VERSION "..\..\trunk\components\winTestMT\code\canApi\dbcFiles\canBus_06.dbc, created by Octave and generateRandomDbc.m on 21-Feb-2017"

NS_ :

BS_:

BU_: ECU

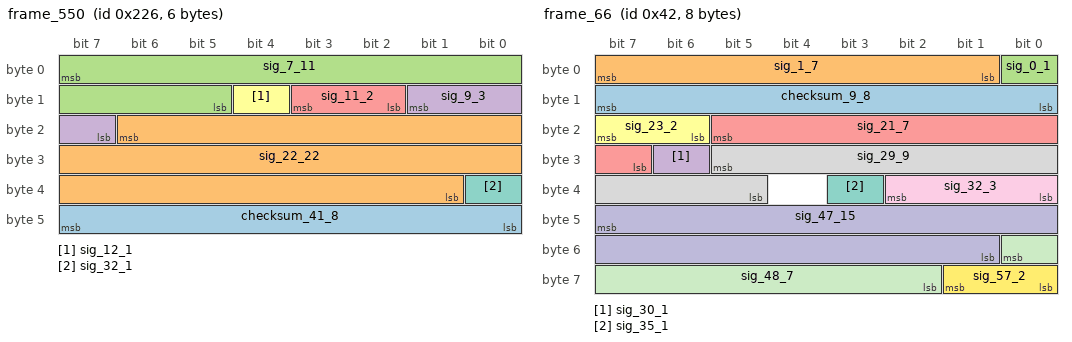
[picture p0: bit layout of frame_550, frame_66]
BO_ 550 frame_550: 6 ECU
  SG_ checksum_41_8 : 47|8@0+ (1.0,0.0) [0.0|255.0] "" Vector__XXX
  SG_ sig_22_22 : 22|22@0+ (1.0000000000000009E-9,0.0) [0.0|0.004194302000000004] "W" Vector__XXX
  SG_ sig_7_11 : 7|11@0- (0.010000000000000002,-3.1622776601683795) [-13.402277660168382|7.0577223398316224] "km/h" Vector__XXX
  SG_ sig_9_3 : 9|3@0+ (1.0,0.0) [0.0|6.0] "" Vector__XXX
  SG_ sig_11_2 : 11|2@0- (1.0,0.0) [-2.0|1.0] "" Vector__XXX
  SG_ sig_12_1 : 12|1@0+ (1.0,0.0) [0.0|1.0] "" Vector__XXX
  SG_ sig_32_1 : 32|1@0+ (1.0,0.0) [0.0|1.0] "" Vector__XXX

BO_ 794 frame_794: 7 Vector__XXX
  SG_ checksum_1_8 : 0|8@1+ (1.0,0.0) [0.0|255.0] "" ECU
  SG_ sig_10_17 : 10|17@1+ (1.0000000000000006E-5,0.0) [0.0|1.3107000000000009] "kWh" ECU
  SG_ sig_27_9 : 27|9@1+ (0.1,-31.622776601683793) [-31.622776601683793|19.377223398316207] "km/h" ECU
  SG_ sig_45_11 : 45|11@1+ (1.0000000000000008E-8,3.162277660168379E-6) [3.162277660168379E-6|2.3622277660168395E-5] "A" ECU
  SG_ sig_36_9 : 36|9@1+ (1.0,0.0) [0.0|510.0] "" ECU

BO_ 168 frame_168: 7 ECU
  SG_ checksum_41_8 : 40|8@1+ (1.0,0.0) [0.0|255.0] "" Vector__XXX
  SG_ sig_9_20 : 9|20@1- (1.0000000000000006E-5,0.0) [-5.242880000000003|5.242860000000003] "V" Vector__XXX
  SG_ sig_1_8 : 1|8@1- (1.0,0.0) [-128.0|126.0] "" Vector__XXX
  SG_ sig_29_7 : 29|7@1+ (1.0000000000000005E-4,-0.0031622776601683794) [-0.0031622776601683794|0.009437722339831625] "V" Vector__XXX
  SG_ sig_36_4 : 36|4@1+ (0.010000000000000002,-0.03162277660168379) [-0.03162277660168379|0.10837722339831622] "V" Vector__XXX
  SG_ sig_48_6 : 48|6@1- (1000.0,-31622.776601683792) [-63622.77660168379|-1622.7766016837923] "km/h" Vector__XXX
  SG_ sig_54_2 : 54|2@1+ (1.0,0.0) [0.0|3.0] "" Vector__XXX

BO_ 66 frame_66: 8 ECU
  SG_ checksum_9_8 : 8|8@1+ (1.0,0.0) [0.0|255.0] "" Vector__XXX
  SG_ sig_1_7 : 1|7@1- (0.1,0.0) [-6.4|6.2] "s" Vector__XXX
  SG_ sig_0_1 : 0|1@0+ (1.0,0.0) [0.0|1.0] "" Vector__XXX
  SG_ sig_30_1 : 30|1@1+ (1.0,0.0) [0.0|1.0] "" Vector__XXX
  SG_ sig_21_7 : 21|7@0+ (100.0,-3162.2776601683795) [-3162.2776601683795|9437.72233983162] "kWh" Vector__XXX
  SG_ sig_23_2 : 23|2@0- (1.0,0.0) [-2.0|1.0] "" Vector__XXX
  SG_ sig_35_1 : 35|1@0+ (1.0,0.0) [0.0|1.0] "" Vector__XXX
  SG_ sig_29_9 : 29|9@0- (0.010000000000000002,-3.1622776601683795) [-5.7222776601683805|-0.622277660168379] "A" Vector__XXX
  SG_ sig_32_3 : 32|3@1- (1.0,0.0) [-4.0|2.0] "" Vector__XXX
  SG_ sig_47_15 : 47|15@0+ (1.0000000000000011E-10,3.162277660168379E-6) [3.162277660168379E-6|6.438877660168383E-6] "A" Vector__XXX
  SG_ sig_48_7 : 48|7@0+ (1.0,0.0) [0.0|126.0] "" Vector__XXX
  SG_ sig_57_2 : 57|2@0+ (1.0,0.0) [0.0|3.0] "" Vector__XXX

BO_ 1387 frame_1387: 6 ECU
  SG_ checksum_17_8 : 23|8@0+ (1.0,0.0) [0.0|255.0] "" Vector__XXX
  SG_ sig_0_14 : 0|14@1- (1.0,3162.2776601683795) [-5029.72233983162|11352.27766016838] "V" Vector__XXX
  SG_ sig_14_2 : 14|2@1+ (1.0,0.0) [0.0|3.0] "" Vector__XXX
  SG_ sig_29_14 : 29|14@0- (1.0,0.0) [-8192.0|8190.0] "" Vector__XXX
  SG_ sig_31_2 : 31|2@0- (1.0,0.0) [-2.0|1.0] "" Vector__XXX
  SG_ sig_47_8 : 47|8@0+ (100.0,3162.2776601683795) [3162.2776601683795|28562.27766016838] "W" Vector__XXX

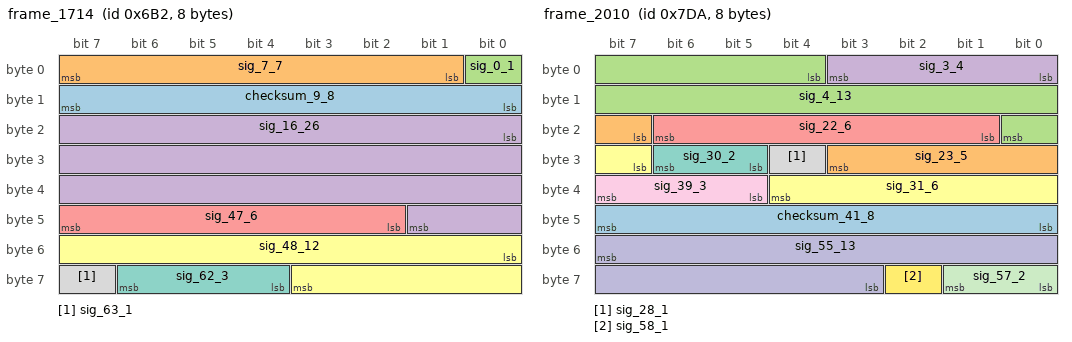
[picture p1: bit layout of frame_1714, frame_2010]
BO_ 1714 frame_1714: 8 Vector__XXX
  SG_ checksum_9_8 : 15|8@0+ (1.0,0.0) [0.0|255.0] "" ECU
  SG_ sig_7_7 : 7|7@0- (1.0,0.0) [-64.0|62.0] "" ECU
  SG_ sig_0_1 : 0|1@0+ (1.0,0.0) [0.0|1.0] "" ECU
  SG_ sig_16_26 : 16|26@1+ (1.0000000000000007E-7,3.1622776601683795) [3.1622776601683795|9.873163860168384] "W" ECU
  SG_ sig_47_6 : 47|6@0+ (1.0000000000000006E-5,0.0) [0.0|6.200000000000003E-4] "s" ECU
  SG_ sig_48_12 : 48|12@1+ (1.0,0.0) [0.0|4094.0] "" ECU
  SG_ sig_62_3 : 62|3@0- (1.0,0.0) [-4.0|2.0] "" ECU
  SG_ sig_63_1 : 63|1@1+ (1.0,0.0) [0.0|1.0] "" ECU

BO_ 2010 frame_2010: 8 Vector__XXX
  SG_ checksum_41_8 : 40|8@1+ (1.0,0.0) [0.0|255.0] "" ECU
  SG_ sig_23_5 : 23|5@1+ (1.0000000000000006E-6,3.1622776601683795E-5) [3.1622776601683795E-5|6.162277660168381E-5] "V" ECU
  SG_ sig_4_13 : 4|13@1- (1.0000000000000008E-8,3.1622776601683795E-5) [-9.33722339831624E-6|7.256277660168383E-5] "s" ECU
  SG_ sig_3_4 : 3|4@0+ (100.0,0.0) [0.0|1400.0] "kWh" ECU
  SG_ sig_22_6 : 22|6@0+ (10.0,316.22776601683796) [316.22776601683796|936.2277660168379] "kWh" ECU
  SG_ sig_31_6 : 31|6@1- (1.0,0.0) [-32.0|30.0] "" ECU
  SG_ sig_30_2 : 30|2@0- (1.0,0.0) [-2.0|1.0] "" ECU
  SG_ sig_28_1 : 28|1@1+ (1.0,0.0) [0.0|1.0] "" ECU
  SG_ sig_39_3 : 39|3@0- (1.0,0.0) [-4.0|2.0] "" ECU
  SG_ sig_55_13 : 55|13@0+ (1.0000000000000005E-4,0.31622776601683794) [0.31622776601683794|1.1352277660168384] "A" ECU
  SG_ sig_57_2 : 57|2@0+ (1.0,0.0) [0.0|3.0] "" ECU
  SG_ sig_58_1 : 58|1@0+ (1.0,0.0) [0.0|1.0] "" ECU

BO_ 300 frame_300: 7 Vector__XXX
  SG_ checksum_49_8 : 55|8@0+ (1.0,0.0) [0.0|255.0] "" ECU
  SG_ sig_12_20 : 12|20@0- (1.0,0.0) [-524288.0|524286.0] "" ECU
  SG_ sig_6_8 : 6|8@0+ (0.010000000000000002,0.0) [0.0|2.5400000000000005] "V" ECU
  SG_ sig_7_1 : 7|1@0+ (1.0,0.0) [0.0|1.0] "" ECU
  SG_ sig_14_2 : 14|2@0+ (1.0,0.0) [0.0|3.0] "" ECU
  SG_ sig_37_14 : 37|14@0+ (0.1,316.22776601683796) [316.22776601683796|1954.427766016838] "m/s^2" ECU
  SG_ sig_24_3 : 24|3@0- (1.0,0.0) [-4.0|2.0] "" ECU

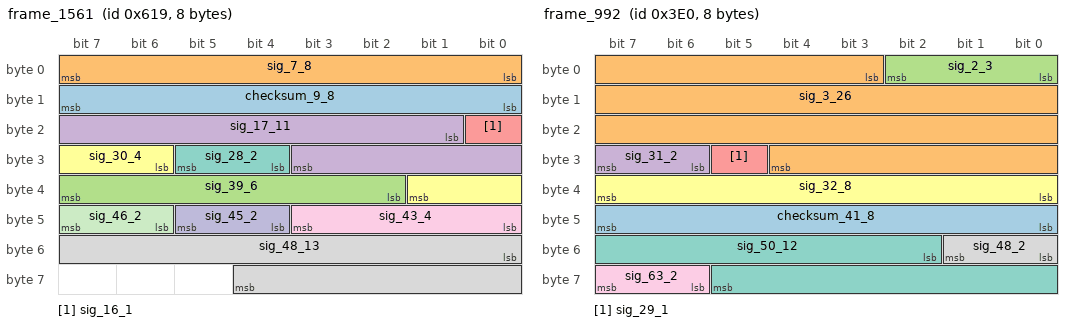
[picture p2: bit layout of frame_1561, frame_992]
BO_ 1561 frame_1561: 8 Vector__XXX
  SG_ checksum_9_8 : 8|8@1+ (1.0,0.0) [0.0|255.0] "" ECU
  SG_ sig_7_8 : 7|8@0- (10.0,0.0) [-1280.0|1260.0] "W" ECU
  SG_ sig_39_6 : 39|6@0- (1.0,0.0) [-32.0|30.0] "" ECU
  SG_ sig_17_11 : 17|11@1- (1.0,0.0) [-1024.0|1022.0] "" ECU
  SG_ sig_16_1 : 16|1@1+ (1.0,0.0) [0.0|1.0] "" ECU
  SG_ sig_30_4 : 30|4@1- (1.0,0.0) [-8.0|6.0] "" ECU
  SG_ sig_28_2 : 28|2@1- (1.0,0.0) [-2.0|1.0] "" ECU
  SG_ sig_48_13 : 48|13@1- (0.010000000000000002,31.622776601683793) [-9.337223398316215|72.5627766016838] "km/h" ECU
  SG_ sig_43_4 : 43|4@0- (1000.0,3162.2776601683795) [-4837.72233983162|9162.27766016838] "km/h" ECU
  SG_ sig_45_2 : 45|2@0+ (1.0,0.0) [0.0|3.0] "" ECU
  SG_ sig_46_2 : 46|2@1- (1.0,0.0) [-2.0|1.0] "" ECU

BO_ 992 frame_992: 8 Vector__XXX
  SG_ checksum_41_8 : 40|8@1+ (1.0,0.0) [0.0|255.0] "" ECU
  SG_ sig_3_26 : 3|26@1- (1.0000000000000005E-4,3162.2776601683795) [-193.16553983162203|6517.720660168381] "kWh" ECU
  SG_ sig_2_3 : 2|3@0+ (1.0,0.0) [0.0|6.0] "" ECU
  SG_ sig_31_2 : 31|2@0- (1.0,0.0) [-2.0|1.0] "" ECU
  SG_ sig_29_1 : 29|1@1+ (1.0,0.0) [0.0|1.0] "" ECU
  SG_ sig_32_8 : 32|8@1- (100.0,-3162.2776601683795) [-15962.27766016838|9437.72233983162] "A" ECU
  SG_ sig_50_12 : 50|12@1+ (1.0,0.0) [0.0|4094.0] "" ECU
  SG_ sig_48_2 : 48|2@1+ (1.0,0.0) [0.0|3.0] "" ECU
  SG_ sig_63_2 : 63|2@0- (1.0,0.0) [-2.0|1.0] "" ECU

BO_ 441 frame_441: 5 ECU
  SG_ checksum_9_8 : 15|8@0+ (1.0,0.0) [0.0|255.0] "" Vector__XXX
  SG_ sig_3_5 : 3|5@1+ (1000.0,-31622.776601683792) [-31622.776601683792|-1622.7766016837923] "m/s^2" Vector__XXX
  SG_ sig_0_3 : 0|3@1- (1.0,0.0) [-4.0|2.0] "" Vector__XXX
  SG_ sig_19_11 : 19|11@1+ (1.0000000000000005E-4,0.03162277660168379) [0.03162277660168379|0.2362227766016839] "kWh" Vector__XXX
  SG_ sig_16_3 : 16|3@1- (1.0,0.0) [-4.0|2.0] "" Vector__XXX
  SG_ sig_31_2 : 31|2@0- (1.0,0.0) [-2.0|1.0] "" Vector__XXX
  SG_ sig_33_7 : 33|7@1- (0.0010000000000000002,0.03162277660168379) [-0.032377223398316224|0.0936227766016838] "kWh" Vector__XXX

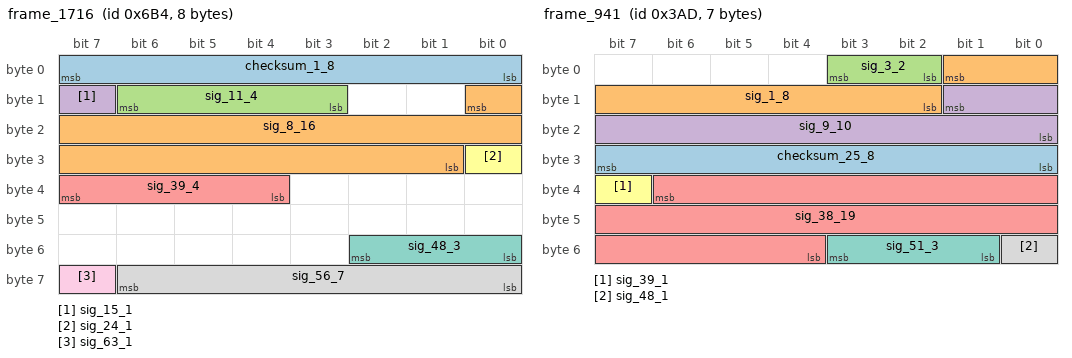
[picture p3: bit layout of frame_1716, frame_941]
BO_ 1716 frame_1716: 8 ECU
  SG_ checksum_1_8 : 0|8@1+ (1.0,0.0) [0.0|255.0] "" Vector__XXX
  SG_ sig_8_16 : 8|16@0+ (1.0,-31622.776601683792) [-31622.776601683792|33911.22339831621] "kWh" Vector__XXX
  SG_ sig_11_4 : 11|4@1- (1.0,0.0) [-8.0|6.0] "" Vector__XXX
  SG_ sig_15_1 : 15|1@0+ (1.0,0.0) [0.0|1.0] "" Vector__XXX
  SG_ sig_39_4 : 39|4@0+ (1.0,0.0) [0.0|14.0] "" Vector__XXX
  SG_ sig_24_1 : 24|1@0+ (1.0,0.0) [0.0|1.0] "" Vector__XXX
  SG_ sig_48_3 : 48|3@1- (1.0,0.0) [-4.0|2.0] "" Vector__XXX
  SG_ sig_56_7 : 56|7@1- (1.0,0.0) [-64.0|62.0] "" Vector__XXX
  SG_ sig_63_1 : 63|1@0+ (1.0,0.0) [0.0|1.0] "" Vector__XXX

BO_ 941 frame_941: 7 ECU
  SG_ checksum_25_8 : 31|8@0+ (1.0,0.0) [0.0|255.0] "" Vector__XXX
  SG_ sig_1_8 : 1|8@0+ (10.0,316.22776601683796) [316.22776601683796|2856.227766016838] "A" Vector__XXX
  SG_ sig_3_2 : 3|2@0- (1.0,0.0) [-2.0|1.0] "" Vector__XXX
  SG_ sig_9_10 : 9|10@0+ (0.0010000000000000002,-0.31622776601683794) [-0.31622776601683794|0.7057722339831622] "V" Vector__XXX
  SG_ sig_38_19 : 38|19@0- (0.1,-31622.776601683792) [-57837.176601683794|-5408.5766016837915] "s" Vector__XXX
  SG_ sig_39_1 : 39|1@0+ (1.0,0.0) [0.0|1.0] "" Vector__XXX
  SG_ sig_51_3 : 51|3@0+ (1.0,0.0) [0.0|6.0] "" Vector__XXX
  SG_ sig_48_1 : 48|1@0+ (1.0,0.0) [0.0|1.0] "" Vector__XXX

BO_ 157 frame_157: 6 Vector__XXX
  SG_ checksum_41_8 : 47|8@0+ (1.0,0.0) [0.0|255.0] "" ECU
  SG_ sig_14_26 : 14|26@0- (1.0000000000000007E-7,-3.1622776601683795) [-6.517720860168382|0.19316533983162287] "V" ECU
  SG_ sig_7_9 : 7|9@0+ (100.0,31622.776601683792) [31622.776601683792|82622.77660168378] "kWh" ECU
  SG_ sig_32_5 : 32|5@1+ (0.010000000000000002,-0.31622776601683794) [-0.31622776601683794|-0.016227766016837897] "kWh" ECU

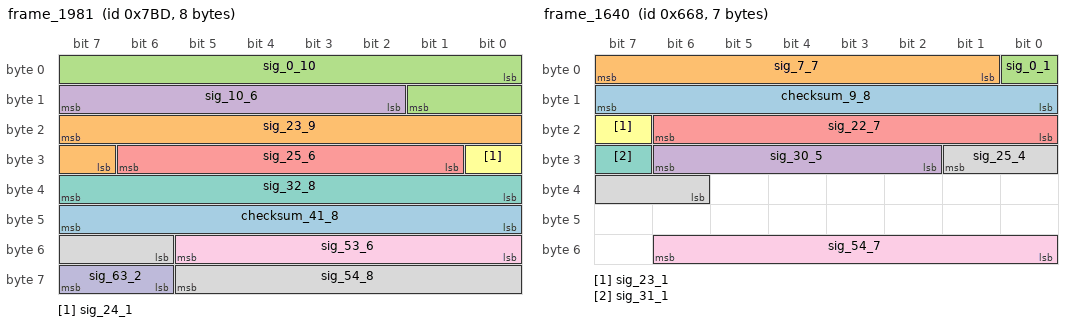
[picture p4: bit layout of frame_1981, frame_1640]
BO_ 1981 frame_1981: 8 Vector__XXX
  SG_ checksum_41_8 : 47|8@0+ (1.0,0.0) [0.0|255.0] "" ECU
  SG_ sig_23_9 : 23|9@0+ (1.0,316.22776601683796) [316.22776601683796|826.2277660168379] "W" ECU
  SG_ sig_0_10 : 0|10@1+ (1.0,0.0) [0.0|1022.0] "" ECU
  SG_ sig_10_6 : 10|6@1+ (1.0,0.0) [0.0|62.0] "m/s^2" ECU
  SG_ sig_25_6 : 25|6@1+ (1.0,0.0) [0.0|62.0] "" ECU
  SG_ sig_24_1 : 24|1@1+ (1.0,0.0) [0.0|1.0] "" ECU
  SG_ sig_32_8 : 32|8@1- (1.0,0.0) [-128.0|126.0] "" ECU
  SG_ sig_54_8 : 54|8@1+ (1.0,-31.622776601683793) [-31.622776601683793|222.3772233983162] "km/h" ECU
  SG_ sig_53_6 : 53|6@0- (1.0000000000000005E-4,-0.0031622776601683794) [-0.006362277660168381|-1.6227766016837803E-4] "W" ECU
  SG_ sig_63_2 : 63|2@0+ (1.0,0.0) [0.0|3.0] "" ECU

BO_ 1640 frame_1640: 7 ECU
  SG_ checksum_9_8 : 15|8@0+ (1.0,0.0) [0.0|255.0] "" Vector__XXX
  SG_ sig_7_7 : 7|7@0- (10.0,0.0) [-640.0|620.0] "V" Vector__XXX
  SG_ sig_0_1 : 0|1@0+ (1.0,0.0) [0.0|1.0] "" Vector__XXX
  SG_ sig_30_5 : 30|5@0+ (1.0,0.0) [0.0|30.0] "" Vector__XXX
  SG_ sig_22_7 : 22|7@0+ (0.1,0.0) [0.0|12.600000000000001] "V" Vector__XXX
  SG_ sig_23_1 : 23|1@0+ (1.0,0.0) [0.0|1.0] "" Vector__XXX
  SG_ sig_31_1 : 31|1@0+ (1.0,0.0) [0.0|1.0] "" Vector__XXX
  SG_ sig_25_4 : 25|4@0- (1.0,0.0) [-8.0|6.0] "" Vector__XXX
  SG_ sig_54_7 : 54|7@0+ (1.0,0.0) [0.0|126.0] "" Vector__XXX

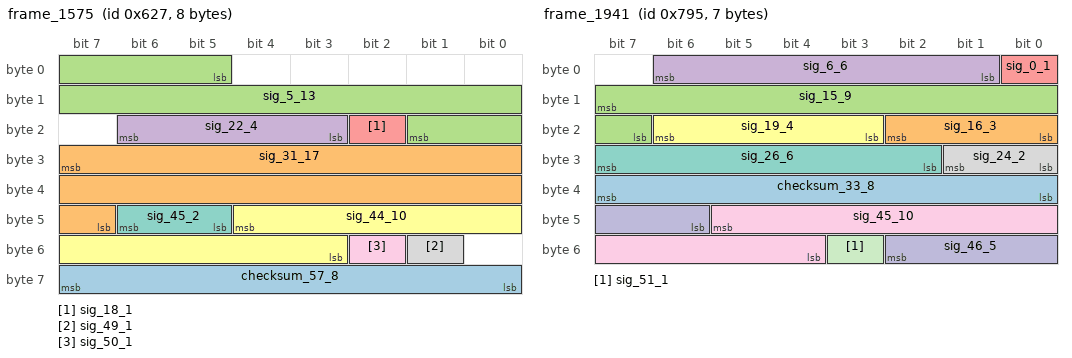
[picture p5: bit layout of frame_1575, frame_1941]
BO_ 1575 frame_1575: 8 ECU
  SG_ checksum_57_8 : 56|8@1+ (1.0,0.0) [0.0|255.0] "" Vector__XXX
  SG_ sig_31_17 : 31|17@0- (1.0,31622.776601683792) [-33913.22339831621|97156.77660168378] "W" Vector__XXX
  SG_ sig_5_13 : 5|13@1- (1.0,0.0) [-4096.0|4094.0] "" Vector__XXX
  SG_ sig_22_4 : 22|4@0+ (10000.0,-31622.776601683792) [-31622.776601683792|108377.22339831622] "kWh" Vector__XXX
  SG_ sig_18_1 : 18|1@0+ (1.0,0.0) [0.0|1.0] "" Vector__XXX
  SG_ sig_44_10 : 44|10@0- (1.0,316.22776601683796) [-195.77223398316204|826.2277660168379] "W" Vector__XXX
  SG_ sig_45_2 : 45|2@1- (1.0,0.0) [-2.0|1.0] "" Vector__XXX
  SG_ sig_49_1 : 49|1@1+ (1.0,0.0) [0.0|1.0] "" Vector__XXX
  SG_ sig_50_1 : 50|1@0+ (1.0,0.0) [0.0|1.0] "" Vector__XXX

BO_ 1169 frame_1169: 8 Vector__XXX
  SG_ checksum_49_8 : 48|8@1+ (1.0,0.0) [0.0|255.0] "" ECU
  SG_ sig_4_20 : 4|20@0- (0.1,-31622.776601683792) [-84051.5766016838|20805.823398316214] "s" ECU
  SG_ sig_5_2 : 5|2@1- (1.0,0.0) [-2.0|1.0] "" ECU
  SG_ sig_29_19 : 29|19@0- (1.0000000000000006E-6,0.31622776601683794) [0.054083766016837787|0.5783697660168381] "kWh" ECU
  SG_ sig_16_1 : 16|1@1+ (1.0,0.0) [0.0|1.0] "" ECU
  SG_ sig_31_2 : 31|2@0- (1.0,0.0) [-2.0|1.0] "" ECU
  SG_ sig_56_7 : 56|7@1+ (1.0000000000000005E-4,-0.0031622776601683794) [-0.0031622776601683794|0.009437722339831625] "kWh" ECU

BO_ 1941 frame_1941: 7 Vector__XXX
  SG_ checksum_33_8 : 39|8@0+ (1.0,0.0) [0.0|255.0] "" ECU
  SG_ sig_16_3 : 16|3@1+ (1.0,0.0) [0.0|6.0] "" ECU
  SG_ sig_15_9 : 15|9@0- (1.0,0.0) [-256.0|254.0] "" ECU
  SG_ sig_6_6 : 6|6@0+ (100.0,0.0) [0.0|6200.0] "V" ECU
  SG_ sig_0_1 : 0|1@1+ (1.0,0.0) [0.0|1.0] "" ECU
  SG_ sig_19_4 : 19|4@1- (1.0,-3.1622776601683795) [-11.16227766016838|2.8377223398316205] "V" ECU
  SG_ sig_26_6 : 26|6@1+ (10.0,-316.22776601683796) [-316.22776601683796|303.77223398316204] "m/s^2" ECU
  SG_ sig_24_2 : 24|2@1- (1.0,0.0) [-2.0|1.0] "" ECU
  SG_ sig_45_10 : 45|10@0- (1.0000000000000007E-7,0.0) [-5.120000000000004E-5|5.100000000000004E-5] "s" ECU
  SG_ sig_46_5 : 46|5@1+ (10.0,0.0) [0.0|300.0] "W" ECU
  SG_ sig_51_1 : 51|1@0+ (1.0,0.0) [0.0|1.0] "" ECU

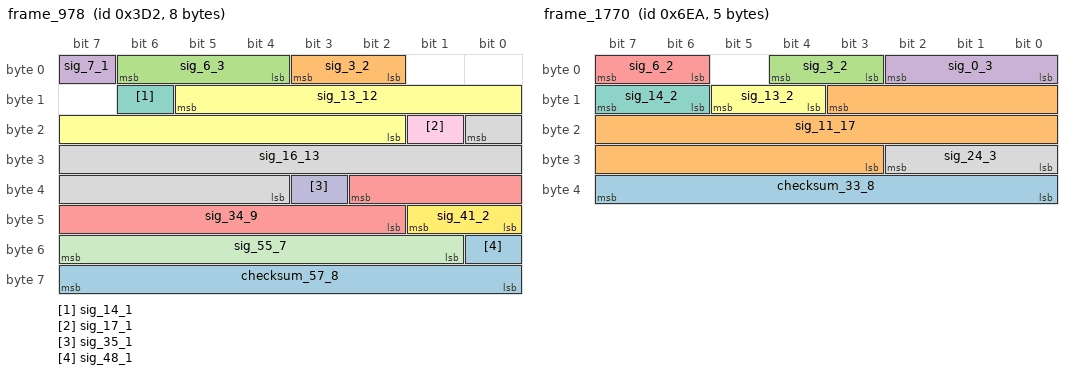
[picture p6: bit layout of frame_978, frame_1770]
BO_ 978 frame_978: 8 Vector__XXX
  SG_ checksum_57_8 : 63|8@0+ (1.0,0.0) [0.0|255.0] "" ECU
  SG_ sig_3_2 : 3|2@0+ (1.0,0.0) [0.0|3.0] "" ECU
  SG_ sig_6_3 : 6|3@0- (1.0,0.0) [-4.0|2.0] "" ECU
  SG_ sig_7_1 : 7|1@0+ (1.0,0.0) [0.0|1.0] "" ECU
  SG_ sig_34_9 : 34|9@0+ (1.0000000000000008E-8,0.0) [0.0|5.1000000000000045E-6] "s" ECU
  SG_ sig_13_12 : 13|12@0+ (1.0,0.0) [0.0|4094.0] "" ECU
  SG_ sig_14_1 : 14|1@0+ (1.0,0.0) [0.0|1.0] "" ECU
  SG_ sig_16_13 : 16|13@0- (1.0000000000000005E-4,0.31622776601683794) [-0.09337223398316224|0.7256277660168382] "m/s^2" ECU
  SG_ sig_17_1 : 17|1@0+ (1.0,0.0) [0.0|1.0] "" ECU
  SG_ sig_35_1 : 35|1@0+ (1.0,0.0) [0.0|1.0] "" ECU
  SG_ sig_55_7 : 55|7@0- (1.0,0.0) [-64.0|62.0] "" ECU
  SG_ sig_41_2 : 41|2@0+ (1.0,0.0) [0.0|3.0] "" ECU
  SG_ sig_48_1 : 48|1@0+ (1.0,0.0) [0.0|1.0] "" ECU

BO_ 1155 frame_1155: 5 Vector__XXX
  SG_ checksum_1_8 : 7|8@0+ (1.0,0.0) [0.0|255.0] "" ECU
  SG_ sig_19_19 : 19|19@1- (0.0010000000000000002,316.22776601683796) [54.0837660168379|578.369766016838] "m/s^2" ECU
  SG_ sig_15_5 : 15|5@0- (1.0000000000000006E-5,-3.1622776601683794E-4) [-4.7622776601683803E-4|-1.7622776601683784E-4] "W" ECU
  SG_ sig_8_3 : 8|3@1+ (1.0,0.0) [0.0|6.0] "" ECU
  SG_ sig_16_3 : 16|3@1- (1.0,0.0) [-4.0|2.0] "" ECU
  SG_ sig_39_1 : 39|1@0+ (1.0,0.0) [0.0|1.0] "" ECU
  SG_ sig_38_1 : 38|1@0+ (1.0,0.0) [0.0|1.0] "" ECU

BO_ 1971 frame_1971: 4 Vector__XXX
  SG_ checksum_17_8 : 16|8@1+ (1.0,0.0) [0.0|255.0] "" ECU
  SG_ sig_0_15 : 0|15@1+ (0.1,-3162.2776601683795) [-3162.2776601683795|114.32233983162087] "s" ECU
  SG_ sig_15_1 : 15|1@1+ (1.0,0.0) [0.0|1.0] "" ECU
  SG_ sig_25_7 : 25|7@1+ (1.0000000000000007E-7,0.0) [0.0|1.260000000000001E-5] "A" ECU
  SG_ sig_24_1 : 24|1@1+ (1.0,0.0) [0.0|1.0] "" ECU

BO_ 1838 frame_1838: 7 Vector__XXX
  SG_ checksum_41_8 : 47|8@0+ (1.0,0.0) [0.0|255.0] "" ECU
  SG_ sig_12_20 : 12|20@0+ (1.000000000000001E-11,3.162277660168379E-6) [3.162277660168379E-6|1.364801766016839E-5] "m/s^2" ECU
  SG_ sig_7_7 : 7|7@0+ (1.0000000000000005E-4,-0.0031622776601683794) [-0.0031622776601683794|0.009437722339831625] "V" ECU
  SG_ sig_32_5 : 32|5@1+ (1.0,0.0) [0.0|30.0] "" ECU
  SG_ sig_38_2 : 38|2@0- (1.0,0.0) [-2.0|1.0] "" ECU
  SG_ sig_49_7 : 49|7@1- (1.0,0.0) [-64.0|62.0] "" ECU
  SG_ sig_48_1 : 48|1@0+ (1.0,0.0) [0.0|1.0] "" ECU

BO_ 1770 frame_1770: 5 Vector__XXX
  SG_ checksum_33_8 : 39|8@0+ (1.0,0.0) [0.0|255.0] "" ECU
  SG_ sig_11_17 : 11|17@0+ (0.1,-3162.2776601683795) [-3162.2776601683795|9944.72233983162] "kWh" ECU
  SG_ sig_3_2 : 3|2@1- (1.0,0.0) [-2.0|1.0] "" ECU
  SG_ sig_0_3 : 0|3@1+ (1.0,0.0) [0.0|6.0] "" ECU
  SG_ sig_6_2 : 6|2@1- (1.0,0.0) [-2.0|1.0] "" ECU
  SG_ sig_13_2 : 13|2@0+ (1.0,0.0) [0.0|3.0] "" ECU
  SG_ sig_14_2 : 14|2@1+ (1.0,0.0) [0.0|3.0] "" ECU
  SG_ sig_24_3 : 24|3@1- (1.0,0.0) [-4.0|2.0] "" ECU

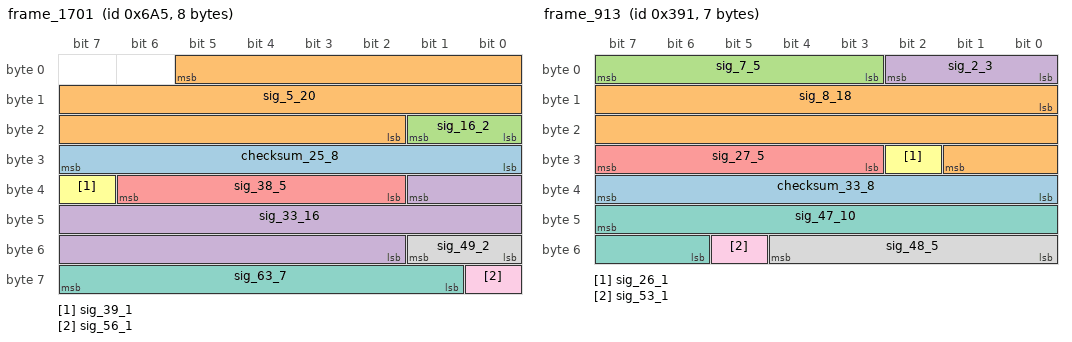
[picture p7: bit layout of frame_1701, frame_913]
BO_ 1701 frame_1701: 8 Vector__XXX
  SG_ checksum_25_8 : 31|8@0+ (1.0,0.0) [0.0|255.0] "" ECU
  SG_ sig_5_20 : 5|20@0+ (1.0,0.0) [0.0|1048574.0] "" ECU
  SG_ sig_16_2 : 16|2@1+ (1.0,0.0) [0.0|3.0] "" ECU
  SG_ sig_33_16 : 33|16@0- (1.0000000000000008E-8,3.1622776601683794E-4) [-1.1452233983162338E-5|6.438877660168382E-4] "W" ECU
  SG_ sig_38_5 : 38|5@0- (1.0,0.0) [-16.0|14.0] "" ECU
  SG_ sig_39_1 : 39|1@1+ (1.0,0.0) [0.0|1.0] "" ECU
  SG_ sig_63_7 : 63|7@0+ (1000.0,0.0) [0.0|126000.0] "A" ECU
  SG_ sig_49_2 : 49|2@0- (1.0,0.0) [-2.0|1.0] "" ECU
  SG_ sig_56_1 : 56|1@0+ (1.0,0.0) [0.0|1.0] "" ECU

BO_ 1727 frame_1727: 4 Vector__XXX
  SG_ checksum_9_8 : 8|8@1+ (1.0,0.0) [0.0|255.0] "" ECU
  SG_ sig_7_7 : 7|7@0+ (1.0,0.0) [0.0|126.0] "" ECU
  SG_ sig_0_1 : 0|1@1+ (1.0,0.0) [0.0|1.0] "" ECU
  SG_ sig_22_6 : 22|6@1+ (100.0,0.0) [0.0|6200.0] "A" ECU
  SG_ sig_17_5 : 17|5@1+ (1.0000000000000005E-4,0.0031622776601683794) [0.0031622776601683794|0.006162277660168381] "A" ECU
  SG_ sig_31_4 : 31|4@0- (10000.0,-31622.776601683792) [-111622.77660168378|28377.223398316208] "V" ECU
  SG_ sig_16_1 : 16|1@1+ (1.0,0.0) [0.0|1.0] "" ECU

BO_ 1329 frame_1329: 4 Vector__XXX
  SG_ checksum_17_8 : 23|8@0+ (1.0,0.0) [0.0|255.0] "" ECU
  SG_ sig_2_11 : 2|11@0- (0.010000000000000002,0.0) [-10.240000000000002|10.220000000000002] "s" ECU
  SG_ sig_3_5 : 3|5@1+ (10.0,0.0) [0.0|300.0] "W" ECU
  SG_ sig_24_7 : 24|7@1+ (1.0000000000000007E-7,-3.162277660168379E-6) [-3.162277660168379E-6|9.43772233983163E-6] "m/s^2" ECU
  SG_ sig_31_1 : 31|1@1+ (1.0,0.0) [0.0|1.0] "" ECU

BO_ 1272 frame_1272: 6 ECU
  SG_ checksum_25_8 : 31|8@0+ (1.0,0.0) [0.0|255.0] "" Vector__XXX
  SG_ sig_4_12 : 4|12@1- (1.0000000000000009E-9,0.0) [-2.048000000000002E-6|2.0460000000000017E-6] "km/h" Vector__XXX
  SG_ sig_2_3 : 2|3@0- (1.0,0.0) [-4.0|2.0] "" Vector__XXX
  SG_ sig_3_1 : 3|1@0+ (1.0,0.0) [0.0|1.0] "" Vector__XXX
  SG_ sig_23_8 : 23|8@0- (1.0000000000000006E-5,-3.1622776601683794E-4) [-0.0015962277660168387|9.437722339831628E-4] "W" Vector__XXX
  SG_ sig_36_12 : 36|12@0+ (1.0000000000000006E-5,0.0) [0.0|0.040940000000000025] "A" Vector__XXX
  SG_ sig_37_4 : 37|4@1- (1.0,0.0) [-8.0|6.0] "" Vector__XXX

BO_ 913 frame_913: 7 ECU
  SG_ checksum_33_8 : 39|8@0+ (1.0,0.0) [0.0|255.0] "" Vector__XXX
  SG_ sig_8_18 : 8|18@1+ (1.0,0.0) [0.0|262142.0] "" Vector__XXX
  SG_ sig_7_5 : 7|5@0- (1.0000000000000007E-7,0.0) [-1.6000000000000012E-6|1.400000000000001E-6] "s" Vector__XXX
  SG_ sig_2_3 : 2|3@0- (1.0,0.0) [-4.0|2.0] "" Vector__XXX
  SG_ sig_27_5 : 27|5@1+ (1.0,31.622776601683793) [31.622776601683793|61.622776601683796] "m/s^2" Vector__XXX
  SG_ sig_26_1 : 26|1@1+ (1.0,0.0) [0.0|1.0] "" Vector__XXX
  SG_ sig_47_10 : 47|10@0+ (1.0,0.0) [0.0|1022.0] "" Vector__XXX
  SG_ sig_48_5 : 48|5@1+ (1.0000000000000006E-5,-3.1622776601683794E-4) [-3.1622776601683794E-4|-1.622776601683775E-5] "kWh" Vector__XXX
  SG_ sig_53_1 : 53|1@0+ (1.0,0.0) [0.0|1.0] "" Vector__XXX

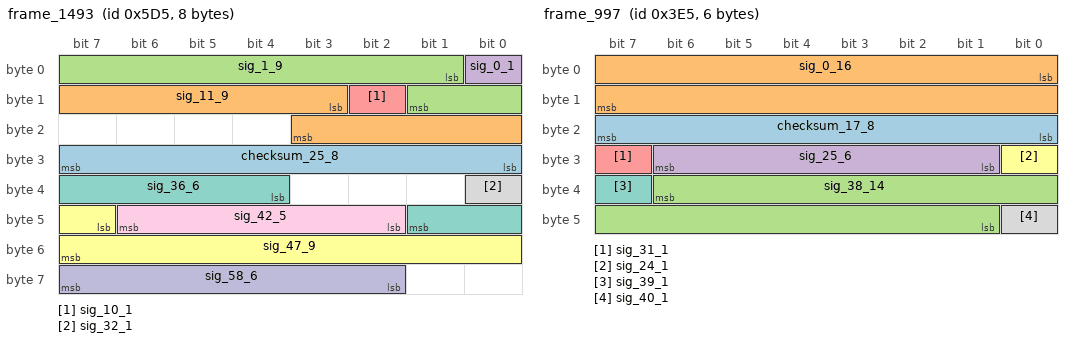
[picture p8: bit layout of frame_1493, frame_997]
BO_ 1493 frame_1493: 8 Vector__XXX
  SG_ checksum_25_8 : 24|8@1+ (1.0,0.0) [0.0|255.0] "" ECU
  SG_ sig_11_9 : 11|9@1- (1.0,0.0) [-256.0|254.0] "" ECU
  SG_ sig_1_9 : 1|9@1+ (1.0000000000000007E-7,3.1622776601683795E-5) [3.1622776601683795E-5|8.262277660168384E-5] "W" ECU
  SG_ sig_0_1 : 0|1@1+ (1.0,0.0) [0.0|1.0] "" ECU
  SG_ sig_10_1 : 10|1@1+ (1.0,0.0) [0.0|1.0] "" ECU
  SG_ sig_47_9 : 47|9@1- (1.0,0.0) [-256.0|254.0] "" ECU
  SG_ sig_36_6 : 36|6@1- (1.0000000000000006E-5,0.0) [-3.200000000000002E-4|3.000000000000002E-4] "m/s^2" ECU
  SG_ sig_32_1 : 32|1@1+ (1.0,0.0) [0.0|1.0] "" ECU
  SG_ sig_42_5 : 42|5@1- (1.0,0.0) [-16.0|14.0] "" ECU
  SG_ sig_58_6 : 58|6@1- (10.0,0.0) [-320.0|300.0] "kWh" ECU

BO_ 1165 frame_1165: 4 ECU
  SG_ checksum_17_8 : 23|8@0+ (1.0,0.0) [0.0|255.0] "" Vector__XXX
  SG_ sig_6_14 : 6|14@0- (0.1,-316.22776601683796) [-1135.427766016838|502.77223398316204] "km/h" Vector__XXX
  SG_ sig_7_1 : 7|1@0+ (1.0,0.0) [0.0|1.0] "" Vector__XXX
  SG_ sig_8_1 : 8|1@0+ (1.0,0.0) [0.0|1.0] "" Vector__XXX
  SG_ sig_31_2 : 31|2@0+ (1.0,0.0) [0.0|3.0] "" Vector__XXX
  SG_ sig_24_1 : 24|1@0+ (1.0,0.0) [0.0|1.0] "" Vector__XXX

BO_ 997 frame_997: 6 Vector__XXX
  SG_ checksum_17_8 : 16|8@1+ (1.0,0.0) [0.0|255.0] "" ECU
  SG_ sig_0_16 : 0|16@1- (0.1,3162.2776601683795) [-114.52233983162068|6438.87766016838] "m/s^2" ECU
  SG_ sig_38_14 : 38|14@0+ (1.0000000000000006E-5,0.03162277660168379) [0.03162277660168379|0.1954427766016839] "s" ECU
  SG_ sig_25_6 : 25|6@1- (1.0000000000000005E-4,-0.0031622776601683794) [-0.006362277660168381|-1.6227766016837803E-4] "s" ECU
  SG_ sig_31_1 : 31|1@0+ (1.0,0.0) [0.0|1.0] "" ECU
  SG_ sig_24_1 : 24|1@1+ (1.0,0.0) [0.0|1.0] "" ECU
  SG_ sig_39_1 : 39|1@0+ (1.0,0.0) [0.0|1.0] "" ECU
  SG_ sig_40_1 : 40|1@1+ (1.0,0.0) [0.0|1.0] "" ECU

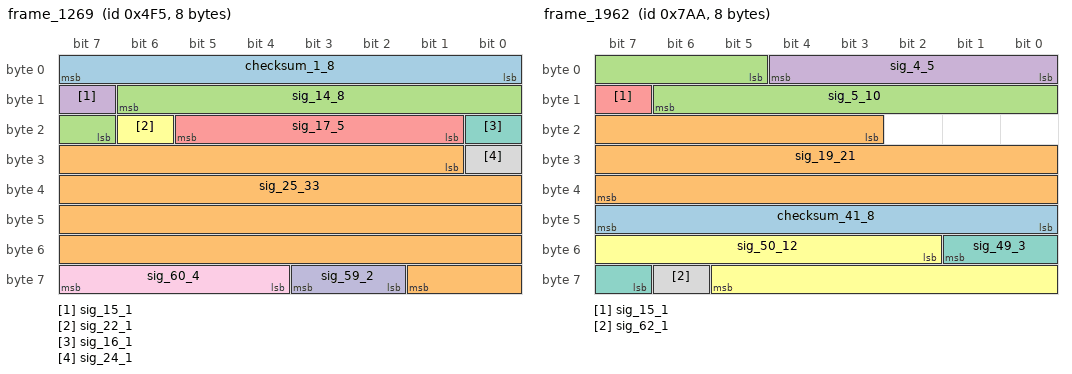
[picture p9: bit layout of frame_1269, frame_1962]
BO_ 1269 frame_1269: 8 Vector__XXX
  SG_ checksum_1_8 : 7|8@0+ (1.0,0.0) [0.0|255.0] "" ECU
  SG_ sig_25_33 : 25|33@1+ (1.0000000000000006E-6,-3162.2776601683795) [-3162.2776601683795|5427.656929831624] "m/s^2" ECU
  SG_ sig_14_8 : 14|8@0+ (1.0000000000000007E-7,-3.162277660168379E-6) [-3.162277660168379E-6|2.2237722339831637E-5] "kWh" ECU
  SG_ sig_15_1 : 15|1@0+ (1.0,0.0) [0.0|1.0] "" ECU
  SG_ sig_17_5 : 17|5@1+ (1.0,0.0) [0.0|30.0] "" ECU
  SG_ sig_22_1 : 22|1@0+ (1.0,0.0) [0.0|1.0] "" ECU
  SG_ sig_16_1 : 16|1@0+ (1.0,0.0) [0.0|1.0] "" ECU
  SG_ sig_24_1 : 24|1@0+ (1.0,0.0) [0.0|1.0] "" ECU
  SG_ sig_60_4 : 60|4@1- (100.0,316.22776601683796) [-483.77223398316204|916.2277660168379] "s" ECU
  SG_ sig_59_2 : 59|2@0+ (1.0,0.0) [0.0|3.0] "" ECU

BO_ 1962 frame_1962: 8 Vector__XXX
  SG_ checksum_41_8 : 47|8@0+ (1.0,0.0) [0.0|255.0] "" ECU
  SG_ sig_19_21 : 19|21@1+ (1.000000000000001E-11,3.162277660168379E-6) [3.162277660168379E-6|2.41337776601684E-5] "km/h" ECU
  SG_ sig_5_10 : 5|10@1+ (10.0,3162.2776601683795) [3162.2776601683795|13382.27766016838] "m/s^2" ECU
  SG_ sig_4_5 : 4|5@0+ (1.0,0.0) [0.0|30.0] "" ECU
  SG_ sig_15_1 : 15|1@0+ (1.0,0.0) [0.0|1.0] "" ECU
  SG_ sig_50_12 : 50|12@1- (1.0000000000000005E-4,-0.31622776601683794) [-0.5210277660168381|-0.11162776601683785] "A" ECU
  SG_ sig_49_3 : 49|3@0+ (1.0,0.0) [0.0|6.0] "" ECU
  SG_ sig_62_1 : 62|1@1+ (1.0,0.0) [0.0|1.0] "" ECU

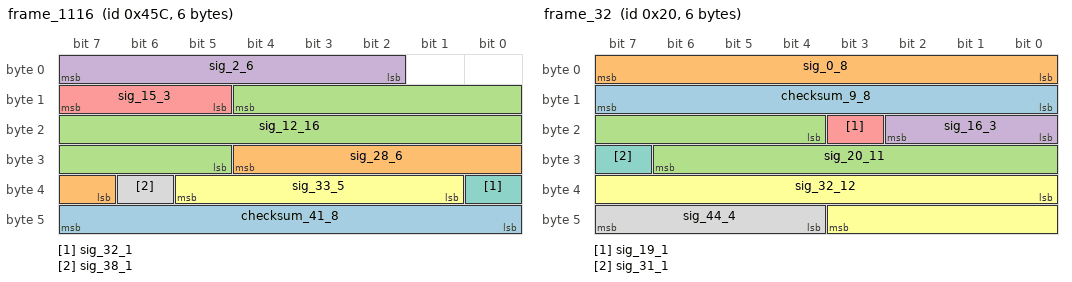
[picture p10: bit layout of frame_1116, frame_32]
BO_ 1116 frame_1116: 6 Vector__XXX
  SG_ checksum_41_8 : 40|8@1+ (1.0,0.0) [0.0|255.0] "" ECU
  SG_ sig_28_6 : 28|6@0- (1.0,-31.622776601683793) [-63.622776601683796|-1.6227766016837926] "kWh" ECU
  SG_ sig_12_16 : 12|16@0- (1.0000000000000006E-5,0.0) [-0.3276800000000002|0.3276600000000002] "W" ECU
  SG_ sig_2_6 : 2|6@1- (0.010000000000000002,-0.31622776601683794) [-0.6362277660168381|-0.016227766016837897] "A" ECU
  SG_ sig_15_3 : 15|3@0+ (1.0,0.0) [0.0|6.0] "" ECU
  SG_ sig_33_5 : 33|5@1- (1.0,0.0) [-16.0|14.0] "" ECU
  SG_ sig_32_1 : 32|1@1+ (1.0,0.0) [0.0|1.0] "" ECU
  SG_ sig_38_1 : 38|1@0+ (1.0,0.0) [0.0|1.0] "" ECU

BO_ 32 frame_32: 6 Vector__XXX
  SG_ checksum_9_8 : 8|8@1+ (1.0,0.0) [0.0|255.0] "" ECU
  SG_ sig_0_8 : 0|8@1+ (1.0,0.0) [0.0|254.0] "" ECU
  SG_ sig_20_11 : 20|11@1- (10.0,0.0) [-10240.0|10220.0] "m/s^2" ECU
  SG_ sig_16_3 : 16|3@1- (1.0,0.0) [-4.0|2.0] "" ECU
  SG_ sig_19_1 : 19|1@1+ (1.0,0.0) [0.0|1.0] "" ECU
  SG_ sig_32_12 : 32|12@1- (1.0,0.0) [-2048.0|2046.0] "" ECU
  SG_ sig_31_1 : 31|1@1+ (1.0,0.0) [0.0|1.0] "" ECU
  SG_ sig_44_4 : 44|4@1+ (1000.0,0.0) [0.0|14000.0] "V" ECU

BO_ 895 frame_895: 3 ECU
  SG_ checksum_9_8 : 8|8@1+ (1.0,0.0) [0.0|255.0] "" Vector__XXX
  SG_ sig_0_5 : 0|5@1+ (0.0010000000000000002,0.0) [0.0|0.030000000000000006] "kWh" Vector__XXX
  SG_ sig_7_3 : 7|3@0+ (1.0,0.0) [0.0|6.0] "" Vector__XXX
  SG_ sig_22_7 : 22|7@0+ (1.0,0.0) [0.0|126.0] "" Vector__XXX
  SG_ sig_23_1 : 23|1@1+ (1.0,0.0) [0.0|1.0] "" Vector__XXX

BO_ 1479 frame_1479: 5 Vector__XXX
  SG_ checksum_1_8 : 7|8@0+ (1.0,0.0) [0.0|255.0] "" ECU
  SG_ sig_23_9 : 23|9@0+ (1.0,0.0) [0.0|510.0] "" ECU
  SG_ sig_8_8 : 8|8@1+ (1.0,0.0) [0.0|254.0] "" ECU
  SG_ sig_27_12 : 27|12@0- (1.0,0.0) [-2048.0|2046.0] "" ECU
  SG_ sig_30_2 : 30|2@0+ (1.0,0.0) [0.0|3.0] "" ECU
  SG_ sig_28_1 : 28|1@0+ (1.0,0.0) [0.0|1.0] "" ECU

BO_ 666 frame_666: 3 ECU
  SG_ checksum_9_8 : 15|8@0+ (1.0,0.0) [0.0|255.0] "" Vector__XXX
  SG_ sig_4_5 : 4|5@0- (100.0,0.0) [-1600.0|1400.0] "V" Vector__XXX
  SG_ sig_5_2 : 5|2@1- (1.0,0.0) [-2.0|1.0] "" Vector__XXX
  SG_ sig_23_7 : 23|7@0- (0.0010000000000000002,0.0) [-0.06400000000000002|0.06200000000000001] "A" Vector__XXX
  SG_ sig_16_1 : 16|1@0+ (1.0,0.0) [0.0|1.0] "" Vector__XXX

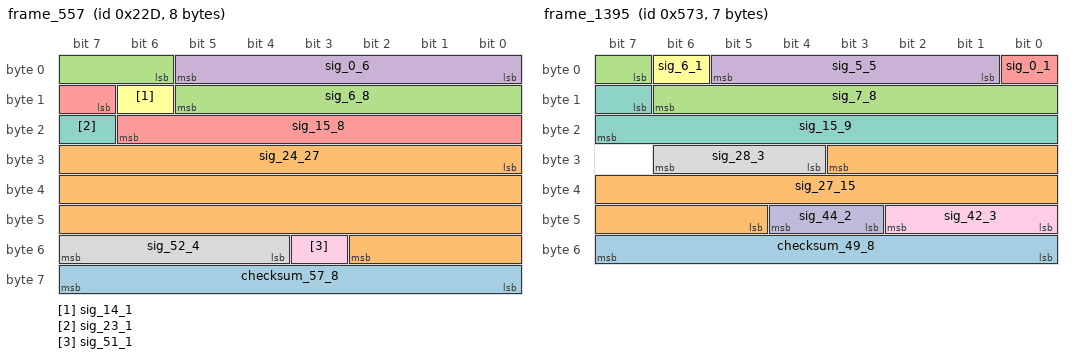
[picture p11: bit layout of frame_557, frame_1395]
BO_ 557 frame_557: 8 Vector__XXX
  SG_ checksum_57_8 : 56|8@1+ (1.0,0.0) [0.0|255.0] "" ECU
  SG_ sig_24_27 : 24|27@1+ (1.0000000000000009E-9,-0.03162277660168379) [-0.03162277660168379|0.10259494939831633] "s" ECU
  SG_ sig_6_8 : 6|8@1+ (1.0,0.0) [0.0|254.0] "" ECU
  SG_ sig_0_6 : 0|6@1- (100.0,3162.2776601683795) [-37.7223398316205|6162.27766016838] "A" ECU
  SG_ sig_15_8 : 15|8@1- (10.0,0.0) [-1280.0|1260.0] "s" ECU
  SG_ sig_14_1 : 14|1@1+ (1.0,0.0) [0.0|1.0] "" ECU
  SG_ sig_23_1 : 23|1@1+ (1.0,0.0) [0.0|1.0] "" ECU
  SG_ sig_52_4 : 52|4@1+ (0.0010000000000000002,-0.0031622776601683794) [-0.0031622776601683794|0.010837722339831624] "kWh" ECU
  SG_ sig_51_1 : 51|1@1+ (1.0,0.0) [0.0|1.0] "" ECU

BO_ 1857 frame_1857: 5 Vector__XXX
  SG_ checksum_1_8 : 7|8@0+ (1.0,0.0) [0.0|255.0] "" ECU
  SG_ sig_21_16 : 21|16@0- (1.0000000000000006E-5,-0.31622776601683794) [-0.6439077660168382|0.011432233983162232] "A" ECU
  SG_ sig_15_10 : 15|10@0+ (0.1,31.622776601683793) [31.622776601683793|133.82277660168378] "kWh" ECU
  SG_ sig_37_5 : 37|5@0- (1000.0,0.0) [-16000.0|14000.0] "km/h" ECU
  SG_ sig_32_1 : 32|1@0+ (1.0,0.0) [0.0|1.0] "" ECU

BO_ 1395 frame_1395: 7 Vector__XXX
  SG_ checksum_49_8 : 48|8@1+ (1.0,0.0) [0.0|255.0] "" ECU
  SG_ sig_27_15 : 27|15@0+ (1.0000000000000007E-7,-0.0031622776601683794) [-0.0031622776601683794|1.1432233983162295E-4] "A" ECU
  SG_ sig_7_8 : 7|8@1+ (1.0,0.0) [0.0|254.0] "" ECU
  SG_ sig_5_5 : 5|5@0- (1.0000000000000005E-4,-0.0031622776601683794) [-0.0047622776601683806|-0.0017622776601683788] "V" ECU
  SG_ sig_0_1 : 0|1@1+ (1.0,0.0) [0.0|1.0] "" ECU
  SG_ sig_6_1 : 6|1@0+ (1.0,0.0) [0.0|1.0] "" ECU
  SG_ sig_15_9 : 15|9@1+ (1.0000000000000005E-4,0.03162277660168379) [0.03162277660168379|0.08262277660168382] "kWh" ECU
  SG_ sig_28_3 : 28|3@1- (1.0,0.0) [-4.0|2.0] "" ECU
  SG_ sig_42_3 : 42|3@0+ (1.0,0.0) [0.0|6.0] "" ECU
  SG_ sig_44_2 : 44|2@0- (1.0,0.0) [-2.0|1.0] "" ECU

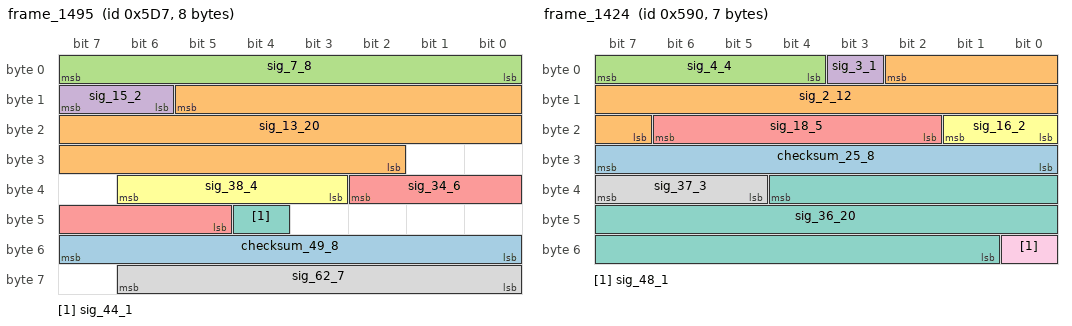
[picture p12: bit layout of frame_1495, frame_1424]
BO_ 1495 frame_1495: 8 ECU
  SG_ checksum_49_8 : 55|8@0+ (1.0,0.0) [0.0|255.0] "" Vector__XXX
  SG_ sig_13_20 : 13|20@0- (1.0000000000000006E-6,-0.31622776601683794) [-0.8405157660168383|0.20805823398316242] "m/s^2" Vector__XXX
  SG_ sig_7_8 : 7|8@0+ (100.0,-3162.2776601683795) [-3162.2776601683795|22237.72233983162] "m/s^2" Vector__XXX
  SG_ sig_15_2 : 15|2@0- (1.0,0.0) [-2.0|1.0] "" Vector__XXX
  SG_ sig_34_6 : 34|6@0- (1.0,0.0) [-32.0|30.0] "" Vector__XXX
  SG_ sig_38_4 : 38|4@0+ (1.0,-3.1622776601683795) [-3.1622776601683795|10.83772233983162] "kWh" Vector__XXX
  SG_ sig_44_1 : 44|1@1+ (1.0,0.0) [0.0|1.0] "" Vector__XXX
  SG_ sig_62_7 : 62|7@0+ (100.0,3162.2776601683795) [3162.2776601683795|15762.27766016838] "V" Vector__XXX

BO_ 457 frame_457: 4 Vector__XXX
  SG_ checksum_25_8 : 24|8@1+ (1.0,0.0) [0.0|255.0] "" ECU
  SG_ sig_13_10 : 13|10@1- (0.0010000000000000002,0.31622776601683794) [-0.19577223398316218|0.826227766016838] "kWh" ECU
  SG_ sig_1_10 : 1|10@1- (1.0,0.0) [-512.0|510.0] "" ECU
  SG_ sig_11_2 : 11|2@1- (1.0,0.0) [-2.0|1.0] "" ECU
  SG_ sig_23_1 : 23|1@1+ (1.0,0.0) [0.0|1.0] "" ECU

BO_ 1175 frame_1175: 5 ECU
  SG_ checksum_1_8 : 0|8@1+ (1.0,0.0) [0.0|255.0] "" Vector__XXX
  SG_ sig_13_12 : 13|12@1- (0.1,316.22776601683796) [111.42776601683795|520.827766016838] "V" Vector__XXX
  SG_ sig_8_4 : 8|4@1- (0.1,-0.31622776601683794) [-1.116227766016838|0.28377223398316215] "kWh" Vector__XXX
  SG_ sig_12_1 : 12|1@1+ (1.0,0.0) [0.0|1.0] "" Vector__XXX
  SG_ sig_25_12 : 25|12@1- (1.0,0.0) [-2048.0|2046.0] "" Vector__XXX
  SG_ sig_37_3 : 37|3@1+ (1.0,0.0) [0.0|6.0] "" Vector__XXX

BO_ 1424 frame_1424: 7 Vector__XXX
  SG_ checksum_25_8 : 24|8@1+ (1.0,0.0) [0.0|255.0] "" ECU
  SG_ sig_2_12 : 2|12@0- (1.0,0.0) [-2048.0|2046.0] "" ECU
  SG_ sig_4_4 : 4|4@1+ (1.0000000000000006E-6,0.0) [0.0|1.4000000000000008E-5] "A" ECU
  SG_ sig_3_1 : 3|1@1+ (1.0,0.0) [0.0|1.0] "" ECU
  SG_ sig_18_5 : 18|5@1+ (1.0000000000000006E-5,3.1622776601683794E-4) [3.1622776601683794E-4|6.162277660168381E-4] "V" ECU
  SG_ sig_16_2 : 16|2@1+ (1.0,0.0) [0.0|3.0] "" ECU
  SG_ sig_36_20 : 36|20@0- (1.0,0.0) [-524288.0|524286.0] "" ECU
  SG_ sig_37_3 : 37|3@1+ (1.0,0.0) [0.0|6.0] "" ECU
  SG_ sig_48_1 : 48|1@1+ (1.0,0.0) [0.0|1.0] "" ECU

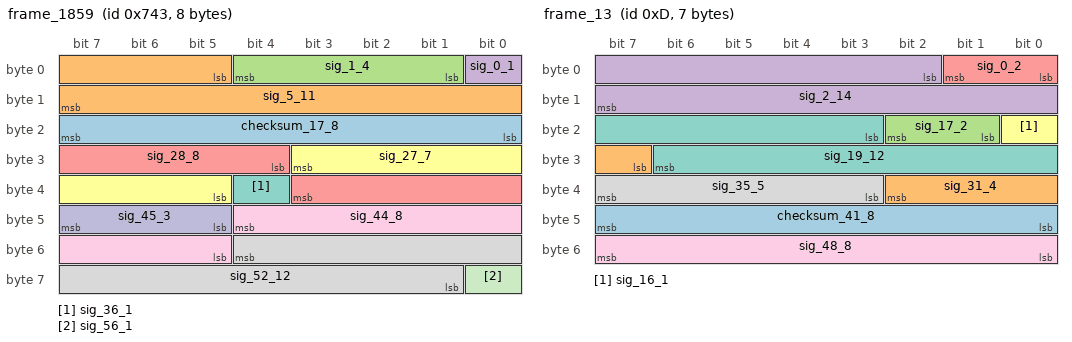
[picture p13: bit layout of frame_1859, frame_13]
BO_ 1859 frame_1859: 8 Vector__XXX
  SG_ checksum_17_8 : 16|8@1+ (1.0,0.0) [0.0|255.0] "" ECU
  SG_ sig_5_11 : 5|11@1- (1.0,0.0) [-1024.0|1022.0] "" ECU
  SG_ sig_1_4 : 1|4@1- (1.0,0.0) [-8.0|6.0] "" ECU
  SG_ sig_0_1 : 0|1@0+ (1.0,0.0) [0.0|1.0] "" ECU
  SG_ sig_28_8 : 28|8@1+ (1.0000000000000005E-4,0.0031622776601683794) [0.0031622776601683794|0.028562277660168393] "A" ECU
  SG_ sig_27_7 : 27|7@0- (1.0,0.0) [-64.0|62.0] "" ECU
  SG_ sig_36_1 : 36|1@1+ (1.0,0.0) [0.0|1.0] "" ECU
  SG_ sig_52_12 : 52|12@0- (0.1,316.22776601683796) [111.42776601683795|520.827766016838] "s" ECU
  SG_ sig_44_8 : 44|8@0+ (10.0,0.0) [0.0|2540.0] "s" ECU
  SG_ sig_45_3 : 45|3@1+ (1.0,0.0) [0.0|6.0] "" ECU
  SG_ sig_56_1 : 56|1@0+ (1.0,0.0) [0.0|1.0] "" ECU

BO_ 985 frame_985: 8 Vector__XXX
  SG_ checksum_1_8 : 7|8@0+ (1.0,0.0) [0.0|255.0] "" ECU
  SG_ sig_20_16 : 20|16@1+ (0.1,3162.2776601683795) [3162.2776601683795|9715.67766016838] "W" ECU
  SG_ sig_12_8 : 12|8@1+ (1000.0,-31622.776601683792) [-31622.776601683792|222377.22339831622] "km/h" ECU
  SG_ sig_11_3 : 11|3@0+ (1.0,0.0) [0.0|6.0] "" ECU
  SG_ sig_8_1 : 8|1@0+ (1.0,0.0) [0.0|1.0] "" ECU
  SG_ sig_37_1 : 37|1@0+ (1.0,0.0) [0.0|1.0] "" ECU
  SG_ sig_63_4 : 63|4@0+ (1.0000000000000006E-5,0.0) [0.0|1.400000000000001E-4] "V" ECU

BO_ 454 frame_454: 7 Vector__XXX
  SG_ checksum_49_8 : 48|8@1+ (1.0,0.0) [0.0|255.0] "" ECU
  SG_ sig_16_26 : 16|26@1+ (1.0000000000000014E-12,3.1622776601683795E-5) [3.1622776601683795E-5|9.873163860168389E-5] "A" ECU
  SG_ sig_13_4 : 13|4@0- (1.0000000000000005E-4,3.1622776601683794E-4) [-4.837722339831624E-4|9.162277660168382E-4] "V" ECU
  SG_ sig_0_10 : 0|10@1- (1.0000000000000006E-5,0.0) [-0.005120000000000003|0.005100000000000003] "km/h" ECU
  SG_ sig_15_2 : 15|2@0- (1.0,0.0) [-2.0|1.0] "" ECU
  SG_ sig_47_6 : 47|6@0+ (1.0,0.0) [0.0|62.0] "" ECU

BO_ 753 frame_753: 5 Vector__XXX
  SG_ checksum_33_8 : 39|8@0+ (1.0,0.0) [0.0|255.0] "" ECU
  SG_ sig_5_16 : 5|16@0+ (0.010000000000000002,316.22776601683796) [316.22776601683796|971.567766016838] "A" ECU
  SG_ sig_7_2 : 7|2@0- (1.0,0.0) [-2.0|1.0] "" ECU
  SG_ sig_20_13 : 20|13@0- (1.0000000000000007E-7,3.1622776601683794E-4) [-9.337223398316237E-5|7.256277660168382E-4] "s" ECU
  SG_ sig_21_1 : 21|1@0+ (1.0,0.0) [0.0|1.0] "" ECU

BO_ 13 frame_13: 7 Vector__XXX
  SG_ checksum_41_8 : 40|8@1+ (1.0,0.0) [0.0|255.0] "" ECU
  SG_ sig_31_4 : 31|4@1- (1.0,0.0) [-8.0|6.0] "" ECU
  SG_ sig_17_2 : 17|2@1- (1.0,0.0) [-2.0|1.0] "" ECU
  SG_ sig_2_14 : 2|14@1+ (0.010000000000000002,-31.622776601683793) [-31.622776601683793|132.19722339831623] "V" ECU
  SG_ sig_0_2 : 0|2@1+ (1.0,0.0) [0.0|3.0] "" ECU
  SG_ sig_16_1 : 16|1@1+ (1.0,0.0) [0.0|1.0] "" ECU
  SG_ sig_19_12 : 19|12@1+ (1.0000000000000006E-5,-0.03162277660168379) [-0.03162277660168379|0.009317223398316234] "W" ECU
  SG_ sig_35_5 : 35|5@1+ (100.0,-3162.2776601683795) [-3162.2776601683795|-162.2776601683795] "V" ECU
  SG_ sig_48_8 : 48|8@1+ (1.0000000000000006E-5,0.0) [0.0|0.0025400000000000015] "kWh" ECU

BO_ 1277 frame_1277: 2 ECU
  SG_ checksum_1_8 : 7|8@0+ (1.0,0.0) [0.0|255.0] "" Vector__XXX
  SG_ sig_15_5 : 15|5@0- (1.0000000000000005E-4,0.0) [-0.0016000000000000007|0.0014000000000000006] "kWh" Vector__XXX
  SG_ sig_10_3 : 10|3@0+ (1.0,0.0) [0.0|6.0] "" Vector__XXX

BO_ 1593 frame_1593: 5 ECU
  SG_ checksum_9_8 : 15|8@0+ (1.0,0.0) [0.0|255.0] "" Vector__XXX
  SG_ sig_3_5 : 3|5@1+ (0.010000000000000002,-0.31622776601683794) [-0.31622776601683794|-0.016227766016837897] "A" Vector__XXX
  SG_ sig_0_3 : 0|3@1+ (1.0,0.0) [0.0|6.0] "" Vector__XXX
  SG_ sig_19_18 : 19|18@0+ (1.0,0.0) [0.0|262142.0] "" Vector__XXX
  SG_ sig_21_3 : 21|3@1+ (1.0,0.0) [0.0|6.0] "" Vector__XXX
  SG_ sig_33_2 : 33|2@0- (1.0,0.0) [-2.0|1.0] "" Vector__XXX

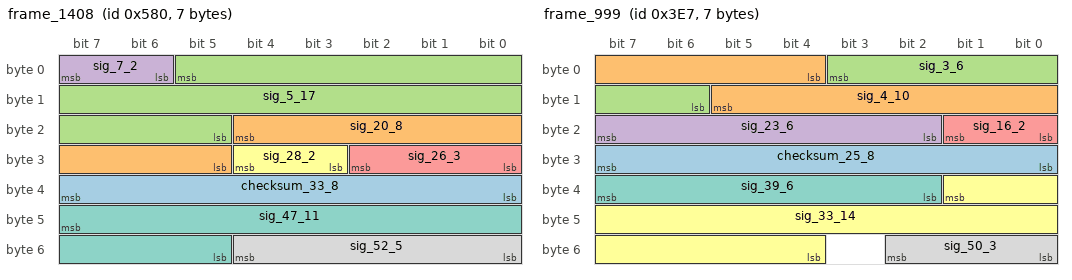
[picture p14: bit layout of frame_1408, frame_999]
BO_ 1408 frame_1408: 7 Vector__XXX
  SG_ checksum_33_8 : 39|8@0+ (1.0,0.0) [0.0|255.0] "" ECU
  SG_ sig_20_8 : 20|8@0- (1.0,0.0) [-128.0|126.0] "" ECU
  SG_ sig_5_17 : 5|17@0- (1.0,0.0) [-65536.0|65534.0] "s" ECU
  SG_ sig_7_2 : 7|2@0- (1.0,0.0) [-2.0|1.0] "" ECU
  SG_ sig_26_3 : 26|3@0+ (1.0,0.0) [0.0|6.0] "" ECU
  SG_ sig_28_2 : 28|2@0- (1.0,0.0) [-2.0|1.0] "" ECU
  SG_ sig_47_11 : 47|11@0- (1.0,0.0) [-1024.0|1022.0] "" ECU
  SG_ sig_52_5 : 52|5@0+ (0.010000000000000002,-0.31622776601683794) [-0.31622776601683794|-0.016227766016837897] "s" ECU

BO_ 999 frame_999: 7 Vector__XXX
  SG_ checksum_25_8 : 24|8@1+ (1.0,0.0) [0.0|255.0] "" ECU
  SG_ sig_4_10 : 4|10@1+ (0.0010000000000000002,-0.31622776601683794) [-0.31622776601683794|0.7057722339831622] "A" ECU
  SG_ sig_3_6 : 3|6@0- (1.0,0.0) [-32.0|30.0] "" ECU
  SG_ sig_23_6 : 23|6@0+ (1000.0,31622.776601683792) [31622.776601683792|93622.77660168378] "V" ECU
  SG_ sig_16_2 : 16|2@1- (1.0,0.0) [-2.0|1.0] "" ECU
  SG_ sig_33_14 : 33|14@0- (0.0010000000000000002,3.1622776601683795) [-5.029722339831622|11.352277660168381] "kWh" ECU
  SG_ sig_39_6 : 39|6@0+ (100.0,0.0) [0.0|6200.0] "km/h" ECU
  SG_ sig_50_3 : 50|3@0+ (1.0,0.0) [0.0|6.0] "" ECU

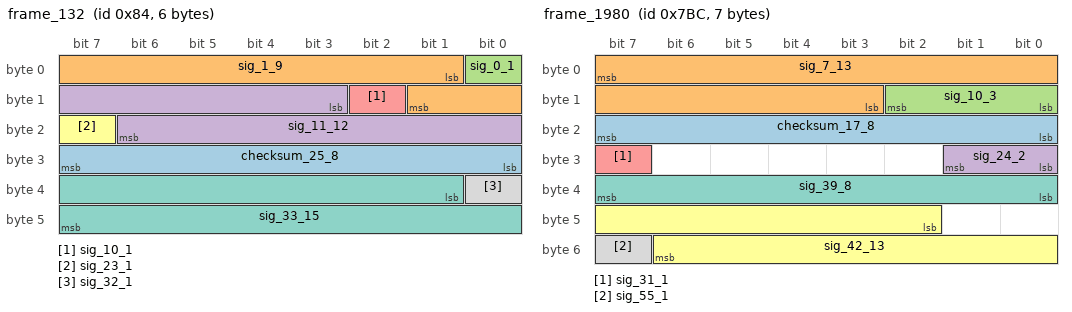
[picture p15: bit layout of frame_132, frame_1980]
BO_ 132 frame_132: 6 Vector__XXX
  SG_ checksum_25_8 : 24|8@1+ (1.0,0.0) [0.0|255.0] "" ECU
  SG_ sig_1_9 : 1|9@1- (1.0000000000000008E-8,-3.162277660168379E-6) [-5.722277660168382E-6|-6.222776601683768E-7] "s" ECU
  SG_ sig_0_1 : 0|1@1+ (1.0,0.0) [0.0|1.0] "" ECU
  SG_ sig_11_12 : 11|12@1- (1.0000000000000005E-4,0.31622776601683794) [0.11142776601683785|0.520827766016838] "km/h" ECU
  SG_ sig_10_1 : 10|1@1+ (1.0,0.0) [0.0|1.0] "" ECU
  SG_ sig_23_1 : 23|1@0+ (1.0,0.0) [0.0|1.0] "" ECU
  SG_ sig_33_15 : 33|15@1- (1.0,0.0) [-16384.0|16382.0] "" ECU
  SG_ sig_32_1 : 32|1@0+ (1.0,0.0) [0.0|1.0] "" ECU

BO_ 1980 frame_1980: 7 ECU
  SG_ checksum_17_8 : 23|8@0+ (1.0,0.0) [0.0|255.0] "" Vector__XXX
  SG_ sig_7_13 : 7|13@0- (1.0000000000000006E-6,-0.0031622776601683794) [-0.007258277660168382|9.317223398316228E-4] "kWh" Vector__XXX
  SG_ sig_10_3 : 10|3@0- (1.0,0.0) [-4.0|2.0] "" Vector__XXX
  SG_ sig_24_2 : 24|2@1- (1.0,0.0) [-2.0|1.0] "" Vector__XXX
  SG_ sig_31_1 : 31|1@0+ (1.0,0.0) [0.0|1.0] "" Vector__XXX
  SG_ sig_42_13 : 42|13@1- (1.0000000000000007E-7,0.0) [-4.096000000000003E-4|4.094000000000003E-4] "s" Vector__XXX
  SG_ sig_39_8 : 39|8@0- (0.0010000000000000002,0.0) [-0.12800000000000003|0.12600000000000003] "s" Vector__XXX
  SG_ sig_55_1 : 55|1@0+ (1.0,0.0) [0.0|1.0] "" Vector__XXX

BO_ 553 frame_553: 6 Vector__XXX
  SG_ checksum_41_8 : 47|8@0+ (1.0,0.0) [0.0|255.0] "" ECU
  SG_ sig_1_12 : 1|12@0- (1.0000000000000006E-5,0.03162277660168379) [0.01114277660168378|0.052082776601683804] "m/s^2" ECU
  SG_ sig_7_6 : 7|6@0- (1.0000000000000005E-4,0.0) [-0.0032000000000000015|0.0030000000000000014] "W" ECU
  SG_ sig_31_14 : 31|14@0- (1.0,0.0) [-8192.0|8190.0] "" ECU
  SG_ sig_21_5 : 21|5@0+ (1.0000000000000005E-4,0.0031622776601683794) [0.0031622776601683794|0.006162277660168381] "A" ECU
  SG_ sig_16_1 : 16|1@0+ (1.0,0.0) [0.0|1.0] "" ECU
  SG_ sig_33_2 : 33|2@0+ (1.0,0.0) [0.0|3.0] "" ECU

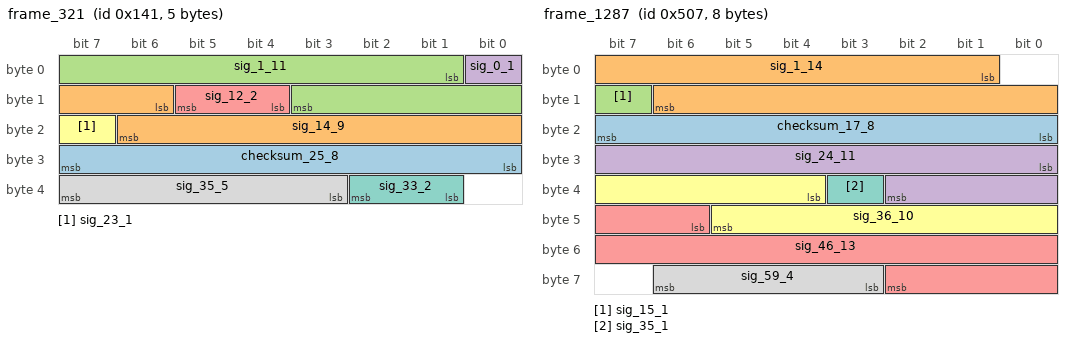
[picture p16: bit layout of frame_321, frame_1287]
BO_ 321 frame_321: 5 Vector__XXX
  SG_ checksum_25_8 : 24|8@1+ (1.0,0.0) [0.0|255.0] "" ECU
  SG_ sig_14_9 : 14|9@1- (1.0,0.0) [-256.0|254.0] "" ECU
  SG_ sig_1_11 : 1|11@1- (0.010000000000000002,3.1622776601683795) [-7.077722339831622|13.382277660168382] "kWh" ECU
  SG_ sig_0_1 : 0|1@1+ (1.0,0.0) [0.0|1.0] "" ECU
  SG_ sig_12_2 : 12|2@1- (1.0,0.0) [-2.0|1.0] "" ECU
  SG_ sig_23_1 : 23|1@1+ (1.0,0.0) [0.0|1.0] "" ECU
  SG_ sig_33_2 : 33|2@1- (1.0,0.0) [-2.0|1.0] "" ECU
  SG_ sig_35_5 : 35|5@1+ (1000.0,31622.776601683792) [31622.776601683792|61622.77660168379] "A" ECU

BO_ 1552 frame_1552: 4 Vector__XXX
  SG_ checksum_9_8 : 8|8@1+ (1.0,0.0) [0.0|255.0] "" ECU
  SG_ sig_0_8 : 0|8@1- (1.0,0.0) [-128.0|126.0] "" ECU
  SG_ sig_23_12 : 23|12@0- (1.0,0.0) [-2048.0|2046.0] "" ECU
  SG_ sig_24_4 : 24|4@1- (1000.0,-3162.2776601683795) [-11162.27766016838|2837.7223398316205] "V" ECU

BO_ 1287 frame_1287: 8 ECU
  SG_ checksum_17_8 : 16|8@1+ (1.0,0.0) [0.0|255.0] "" Vector__XXX
  SG_ sig_1_14 : 1|14@1+ (1.0000000000000006E-5,0.03162277660168379) [0.03162277660168379|0.1954427766016839] "km/h" Vector__XXX
  SG_ sig_15_1 : 15|1@1+ (1.0,0.0) [0.0|1.0] "" Vector__XXX
  SG_ sig_24_11 : 24|11@1- (1.0000000000000007E-7,-3.1622776601683795E-5) [-1.3402277660168387E-4|7.057722339831628E-5] "V" Vector__XXX
  SG_ sig_46_13 : 46|13@1+ (0.1,316.22776601683796) [316.22776601683796|1135.227766016838] "m/s^2" Vector__XXX
  SG_ sig_36_10 : 36|10@1- (0.010000000000000002,3.1622776601683795) [-1.9577223398316215|8.262277660168381] "V" Vector__XXX
  SG_ sig_35_1 : 35|1@1+ (1.0,0.0) [0.0|1.0] "" Vector__XXX
  SG_ sig_59_4 : 59|4@1+ (1.0000000000000006E-5,0.0) [0.0|1.400000000000001E-4] "kWh" Vector__XXX

BO_ 1487 frame_1487: 5 Vector__XXX
  SG_ checksum_25_8 : 24|8@1+ (1.0,0.0) [0.0|255.0] "" ECU
  SG_ sig_0_7 : 0|7@1+ (100.0,0.0) [0.0|12600.0] "W" ECU
  SG_ sig_11_13 : 11|13@1- (1.0000000000000008E-8,0.0) [-4.0960000000000035E-5|4.094000000000003E-5] "m/s^2" ECU
  SG_ sig_32_7 : 32|7@1- (10.0,316.22776601683796) [-323.77223398316204|936.2277660168379] "kWh" ECU
  SG_ sig_39_1 : 39|1@1+ (1.0,0.0) [0.0|1.0] "" ECU

BO_ 1225 frame_1225: 4 Vector__XXX
  SG_ checksum_1_8 : 7|8@0+ (1.0,0.0) [0.0|255.0] "" ECU
  SG_ sig_16_7 : 16|7@0+ (0.0010000000000000002,0.0) [0.0|0.12600000000000003] "A" ECU
  SG_ sig_11_10 : 11|10@0+ (0.1,-31.622776601683793) [-31.622776601683793|70.5772233983162] "s" ECU
  SG_ sig_14_3 : 14|3@0- (1.0,0.0) [-4.0|2.0] "" ECU
  SG_ sig_15_1 : 15|1@0+ (1.0,0.0) [0.0|1.0] "" ECU
  SG_ sig_24_2 : 24|2@1+ (1.0,0.0) [0.0|3.0] "" ECU

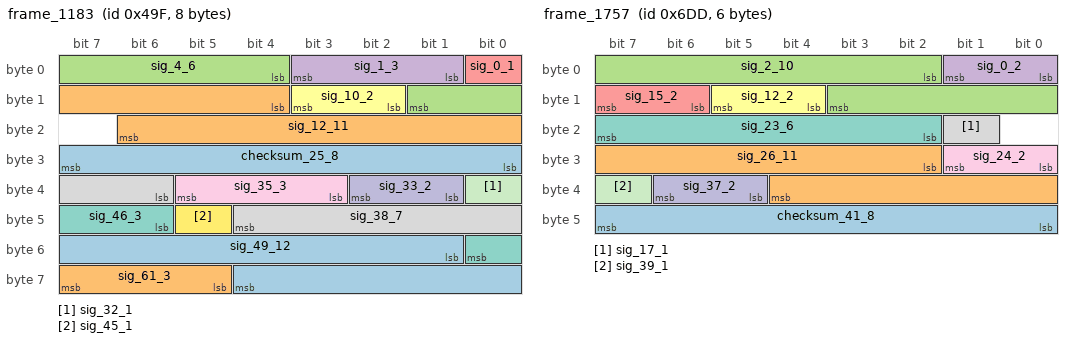
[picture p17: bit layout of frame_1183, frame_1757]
BO_ 1183 frame_1183: 8 Vector__XXX
  SG_ checksum_25_8 : 24|8@1+ (1.0,0.0) [0.0|255.0] "" ECU
  SG_ sig_12_11 : 12|11@1+ (1.0,0.0) [0.0|2046.0] "" ECU
  SG_ sig_4_6 : 4|6@1- (0.0010000000000000002,0.03162277660168379) [-3.7722339831621626E-4|0.0616227766016838] "A" ECU
  SG_ sig_1_3 : 1|3@1+ (1.0,0.0) [0.0|6.0] "" ECU
  SG_ sig_0_1 : 0|1@1+ (1.0,0.0) [0.0|1.0] "" ECU
  SG_ sig_10_2 : 10|2@1+ (1.0,0.0) [0.0|3.0] "" ECU
  SG_ sig_46_3 : 46|3@1- (1.0,0.0) [-4.0|2.0] "" ECU
  SG_ sig_38_7 : 38|7@1- (1.0,0.0) [-64.0|62.0] "" ECU
  SG_ sig_35_3 : 35|3@1+ (1.0,0.0) [0.0|6.0] "" ECU
  SG_ sig_33_2 : 33|2@1+ (1.0,0.0) [0.0|3.0] "" ECU
  SG_ sig_32_1 : 32|1@1+ (1.0,0.0) [0.0|1.0] "" ECU
  SG_ sig_45_1 : 45|1@1+ (1.0,0.0) [0.0|1.0] "" ECU
  SG_ sig_49_12 : 49|12@1- (1.0000000000000009E-9,3.162277660168379E-6) [1.1142776601683774E-6|5.208277660168381E-6] "V" ECU
  SG_ sig_61_3 : 61|3@1- (1.0,0.0) [-4.0|2.0] "" ECU

BO_ 679 frame_679: 5 Vector__XXX
  SG_ checksum_9_8 : 8|8@1+ (1.0,0.0) [0.0|255.0] "" ECU
  SG_ sig_7_8 : 7|8@0+ (0.010000000000000002,0.31622776601683794) [0.31622776601683794|2.8562277660168385] "km/h" ECU
  SG_ sig_22_10 : 22|10@0- (1.0,0.0) [-512.0|510.0] "" ECU
  SG_ sig_24_4 : 24|4@1- (1.0,0.0) [-8.0|6.0] "" ECU
  SG_ sig_23_1 : 23|1@1+ (1.0,0.0) [0.0|1.0] "" ECU
  SG_ sig_28_1 : 28|1@1+ (1.0,0.0) [0.0|1.0] "" ECU
  SG_ sig_32_8 : 32|8@1- (10.0,-316.22776601683796) [-1596.227766016838|943.7722339831621] "W" ECU

BO_ 257 frame_257: 5 Vector__XXX
  SG_ checksum_1_8 : 7|8@0+ (1.0,0.0) [0.0|255.0] "" ECU
  SG_ sig_13_21 : 13|21@0- (1.0000000000000006E-5,0.0) [-10.485760000000006|10.485740000000007] "W" ECU
  SG_ sig_14_1 : 14|1@0+ (1.0,0.0) [0.0|1.0] "" ECU
  SG_ sig_15_1 : 15|1@0+ (1.0,0.0) [0.0|1.0] "" ECU
  SG_ sig_37_6 : 37|6@0+ (1.0,0.0) [0.0|62.0] "" ECU
  SG_ sig_24_3 : 24|3@0- (1.0,0.0) [-4.0|2.0] "" ECU

BO_ 189 frame_189: 2 ECU
  SG_ checksum_9_8 : 15|8@0+ (1.0,0.0) [0.0|255.0] "" Vector__XXX
  SG_ sig_7_7 : 7|7@0- (10.0,316.22776601683796) [-323.77223398316204|936.2277660168379] "km/h" Vector__XXX
  SG_ sig_0_1 : 0|1@0+ (1.0,0.0) [0.0|1.0] "" Vector__XXX

BO_ 494 frame_494: 5 ECU
  SG_ checksum_1_8 : 7|8@0+ (1.0,0.0) [0.0|255.0] "" Vector__XXX
  SG_ sig_8_11 : 8|11@1- (1.0,0.0) [-1024.0|1022.0] "" Vector__XXX
  SG_ sig_20_16 : 20|16@1+ (1.0,0.0) [0.0|65534.0] "" Vector__XXX
  SG_ sig_19_1 : 19|1@0+ (1.0,0.0) [0.0|1.0] "" Vector__XXX
  SG_ sig_39_4 : 39|4@0- (100.0,-316.22776601683796) [-1116.227766016838|283.77223398316204] "V" Vector__XXX

BO_ 1045 frame_1045: 4 ECU
  SG_ checksum_17_8 : 16|8@1+ (1.0,0.0) [0.0|255.0] "" Vector__XXX
  SG_ sig_0_16 : 0|16@1+ (1.0,0.0) [0.0|65534.0] "" Vector__XXX
  SG_ sig_29_5 : 29|5@0+ (1.0000000000000005E-4,0.0) [0.0|0.0030000000000000014] "A" Vector__XXX
  SG_ sig_31_2 : 31|2@0+ (1.0,0.0) [0.0|3.0] "" Vector__XXX

BO_ 1032 frame_1032: 7 Vector__XXX
  SG_ checksum_41_8 : 40|8@1+ (1.0,0.0) [0.0|255.0] "" ECU
  SG_ sig_2_25 : 2|25@1+ (1.0000000000000005E-4,3162.2776601683795) [3162.2776601683795|6517.720660168381] "V" ECU
  SG_ sig_0_2 : 0|2@1+ (1.0,0.0) [0.0|3.0] "" ECU
  SG_ sig_28_11 : 28|11@1- (0.010000000000000002,-3.1622776601683795) [-13.402277660168382|7.0577223398316224] "V" ECU
  SG_ sig_39_1 : 39|1@1+ (1.0,0.0) [0.0|1.0] "" ECU
  SG_ sig_48_6 : 48|6@1- (1.0,0.0) [-32.0|30.0] "" ECU
  SG_ sig_54_2 : 54|2@1+ (1.0,0.0) [0.0|3.0] "" ECU

BO_ 58 frame_58: 3 Vector__XXX
  SG_ checksum_9_8 : 15|8@0+ (1.0,0.0) [0.0|255.0] "" ECU
  SG_ sig_6_7 : 6|7@0- (100.0,3162.2776601683795) [-3237.7223398316205|9362.27766016838] "m/s^2" ECU
  SG_ sig_7_1 : 7|1@1+ (1.0,0.0) [0.0|1.0] "" ECU
  SG_ sig_20_3 : 20|3@1+ (1.0,0.0) [0.0|6.0] "" ECU
  SG_ sig_23_1 : 23|1@0+ (1.0,0.0) [0.0|1.0] "" ECU
  SG_ sig_19_4 : 19|4@0- (0.1,0.31622776601683794) [-0.4837722339831621|0.9162277660168381] "W" ECU

BO_ 313 frame_313: 4 Vector__XXX
  SG_ checksum_25_8 : 24|8@1+ (1.0,0.0) [0.0|255.0] "" ECU
  SG_ sig_6_7 : 6|7@1+ (1.0,0.0) [0.0|126.0] "" ECU
  SG_ sig_0_6 : 0|6@1- (1.0,0.0) [-32.0|30.0] "" ECU
  SG_ sig_14_9 : 14|9@1- (0.010000000000000002,0.0) [-2.5600000000000005|2.5400000000000005] "V" ECU
  SG_ sig_13_1 : 13|1@1+ (1.0,0.0) [0.0|1.0] "" ECU
  SG_ sig_23_1 : 23|1@0+ (1.0,0.0) [0.0|1.0] "" ECU

BO_ 115 frame_115: 4 Vector__XXX
  SG_ checksum_9_8 : 8|8@1+ (1.0,0.0) [0.0|255.0] "" ECU
  SG_ sig_0_8 : 0|8@1+ (0.0010000000000000002,0.03162277660168379) [0.03162277660168379|0.28562277660168384] "kWh" ECU
  SG_ sig_17_14 : 17|14@1- (1.0000000000000005E-4,0.31622776601683794) [-0.5029722339831624|1.1352277660168384] "kWh" ECU
  SG_ sig_16_1 : 16|1@1+ (1.0,0.0) [0.0|1.0] "" ECU
  SG_ sig_31_1 : 31|1@1+ (1.0,0.0) [0.0|1.0] "" ECU

BO_ 1574 frame_1574: 5 Vector__XXX
  SG_ checksum_1_8 : 7|8@0+ (1.0,0.0) [0.0|255.0] "" ECU
  SG_ sig_21_12 : 21|12@0+ (1.0,0.0) [0.0|4094.0] "" ECU
  SG_ sig_15_10 : 15|10@0- (1.0,0.0) [-512.0|510.0] "" ECU
  SG_ sig_24_2 : 24|2@1+ (1.0,0.0) [0.0|3.0] "" ECU
  SG_ sig_32_1 : 32|1@1+ (1.0,0.0) [0.0|1.0] "" ECU

BO_ 1757 frame_1757: 6 Vector__XXX
  SG_ checksum_41_8 : 47|8@0+ (1.0,0.0) [0.0|255.0] "" ECU
  SG_ sig_26_11 : 26|11@1- (1.0000000000000007E-7,0.0) [-1.0240000000000008E-4|1.0220000000000007E-4] "V" ECU
  SG_ sig_2_10 : 2|10@1- (1.0000000000000006E-6,0.0) [-5.120000000000003E-4|5.100000000000003E-4] "s" ECU
  SG_ sig_0_2 : 0|2@1+ (1.0,0.0) [0.0|3.0] "" ECU
  SG_ sig_15_2 : 15|2@0- (1.0,0.0) [-2.0|1.0] "" ECU
  SG_ sig_12_2 : 12|2@1+ (1.0,0.0) [0.0|3.0] "" ECU
  SG_ sig_23_6 : 23|6@0+ (1.0,0.0) [0.0|62.0] "" ECU
  SG_ sig_17_1 : 17|1@0+ (1.0,0.0) [0.0|1.0] "" ECU
  SG_ sig_24_2 : 24|2@1- (1.0,0.0) [-2.0|1.0] "" ECU
  SG_ sig_37_2 : 37|2@1- (1.0,0.0) [-2.0|1.0] "" ECU
  SG_ sig_39_1 : 39|1@0+ (1.0,0.0) [0.0|1.0] "" ECU

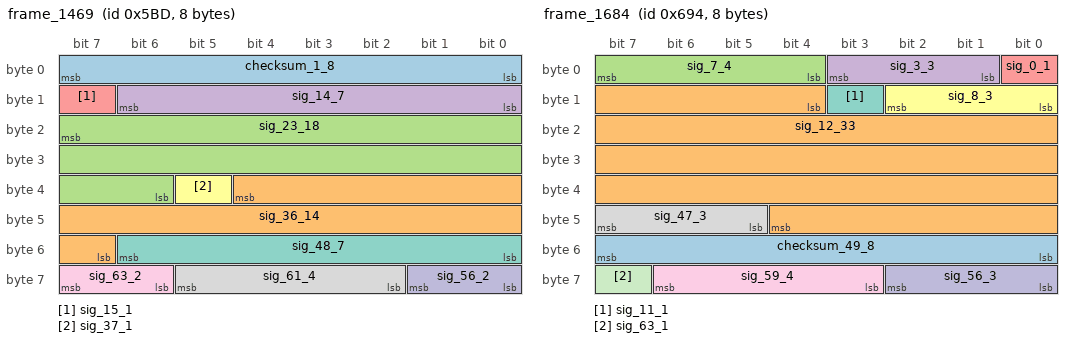
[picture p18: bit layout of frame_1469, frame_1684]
BO_ 1469 frame_1469: 8 ECU
  SG_ checksum_1_8 : 7|8@0+ (1.0,0.0) [0.0|255.0] "" Vector__XXX
  SG_ sig_36_14 : 36|14@0- (1.0000000000000009E-9,0.0) [-8.192000000000007E-6|8.190000000000008E-6] "s" Vector__XXX
  SG_ sig_23_18 : 23|18@0- (1.0,0.0) [-131072.0|131070.0] "" Vector__XXX
  SG_ sig_14_7 : 14|7@0+ (1.0000000000000007E-7,0.0) [0.0|1.260000000000001E-5] "W" Vector__XXX
  SG_ sig_15_1 : 15|1@0+ (1.0,0.0) [0.0|1.0] "" Vector__XXX
  SG_ sig_37_1 : 37|1@1+ (1.0,0.0) [0.0|1.0] "" Vector__XXX
  SG_ sig_48_7 : 48|7@1+ (0.0010000000000000002,0.03162277660168379) [0.03162277660168379|0.15762277660168383] "km/h" Vector__XXX
  SG_ sig_61_4 : 61|4@0+ (1.0,0.0) [0.0|14.0] "" Vector__XXX
  SG_ sig_63_2 : 63|2@0- (1.0,0.0) [-2.0|1.0] "" Vector__XXX
  SG_ sig_56_2 : 56|2@1- (1.0,0.0) [-2.0|1.0] "" Vector__XXX

BO_ 1684 frame_1684: 8 ECU
  SG_ checksum_49_8 : 55|8@0+ (1.0,0.0) [0.0|255.0] "" Vector__XXX
  SG_ sig_12_33 : 12|33@1+ (1.0000000000000014E-12,0.0031622776601683794) [0.0031622776601683794|0.011752212250168391] "W" Vector__XXX
  SG_ sig_7_4 : 7|4@0+ (1000.0,-3162.2776601683795) [-3162.2776601683795|10837.72233983162] "m/s^2" Vector__XXX
  SG_ sig_3_3 : 3|3@0+ (1.0,0.0) [0.0|6.0] "" Vector__XXX
  SG_ sig_0_1 : 0|1@0+ (1.0,0.0) [0.0|1.0] "" Vector__XXX
  SG_ sig_8_3 : 8|3@1- (1.0,0.0) [-4.0|2.0] "" Vector__XXX
  SG_ sig_11_1 : 11|1@0+ (1.0,0.0) [0.0|1.0] "" Vector__XXX
  SG_ sig_47_3 : 47|3@0- (1.0,0.0) [-4.0|2.0] "" Vector__XXX
  SG_ sig_59_4 : 59|4@1- (1.0000000000000006E-6,-3.162277660168379E-6) [-1.1162277660168384E-5|2.8377223398316243E-6] "s" Vector__XXX
  SG_ sig_56_3 : 56|3@1+ (1.0,0.0) [0.0|6.0] "" Vector__XXX
  SG_ sig_63_1 : 63|1@0+ (1.0,0.0) [0.0|1.0] "" Vector__XXX

BO_ 505 frame_505: 4 Vector__XXX
  SG_ checksum_9_8 : 15|8@0+ (1.0,0.0) [0.0|255.0] "" ECU
  SG_ sig_7_8 : 7|8@0- (1.0000000000000007E-7,0.0) [-1.280000000000001E-5|1.260000000000001E-5] "kWh" ECU
  SG_ sig_23_14 : 23|14@0- (1.0,0.0) [-8192.0|8190.0] "" ECU
  SG_ sig_25_2 : 25|2@0+ (1.0,0.0) [0.0|3.0] "" ECU

BO_ 1310 frame_1310: 6 Vector__XXX
  SG_ checksum_17_8 : 16|8@1+ (1.0,0.0) [0.0|255.0] "" ECU
  SG_ sig_6_14 : 6|14@0+ (1.0000000000000008E-8,3.1622776601683795E-5) [3.1622776601683795E-5|1.9544277660168394E-4] "km/h" ECU
  SG_ sig_7_2 : 7|2@1- (1.0,0.0) [-2.0|1.0] "" ECU
  SG_ sig_36_11 : 36|11@0- (1.0000000000000006E-5,0.0031622776601683794) [-0.007077722339831626|0.013382277660168387] "V" ECU
  SG_ sig_26_6 : 26|6@1- (0.010000000000000002,0.0) [-0.32000000000000006|0.30000000000000004] "m/s^2" ECU
  SG_ sig_37_1 : 37|1@0+ (1.0,0.0) [0.0|1.0] "" ECU
  SG_ sig_41_2 : 41|2@0- (1.0,0.0) [-2.0|1.0] "" ECU

BO_ 567 frame_567: 5 Vector__XXX
  SG_ checksum_17_8 : 16|8@1+ (1.0,0.0) [0.0|255.0] "" ECU
  SG_ sig_7_9 : 7|9@1+ (1.0000000000000008E-8,0.0) [0.0|5.1000000000000045E-6] "V" ECU
  SG_ sig_0_7 : 0|7@1+ (1.0,0.0) [0.0|126.0] "" ECU
  SG_ sig_32_8 : 32|8@1- (100.0,0.0) [-12800.0|12600.0] "V" ECU
  SG_ sig_25_6 : 25|6@1- (100.0,-3162.2776601683795) [-6362.27766016838|-162.2776601683795] "W" ECU
  SG_ sig_24_1 : 24|1@1+ (1.0,0.0) [0.0|1.0] "" ECU
  SG_ sig_31_1 : 31|1@1+ (1.0,0.0) [0.0|1.0] "" ECU

BO_ 1632 frame_1632: 3 Vector__XXX
  SG_ checksum_17_8 : 23|8@0+ (1.0,0.0) [0.0|255.0] "" ECU
  SG_ sig_7_9 : 7|9@0+ (0.010000000000000002,0.0) [0.0|5.100000000000001] "km/h" ECU
  SG_ sig_13_6 : 13|6@0- (0.1,0.0) [-3.2|3.0] "V" ECU
  SG_ sig_14_1 : 14|1@0+ (1.0,0.0) [0.0|1.0] "" ECU

BO_ 345 frame_345: 6 Vector__XXX
  SG_ checksum_17_8 : 23|8@0+ (1.0,0.0) [0.0|255.0] "" ECU
  SG_ sig_7_11 : 7|11@0+ (1.0000000000000008E-8,3.162277660168379E-6) [3.162277660168379E-6|2.3622277660168395E-5] "s" ECU
  SG_ sig_38_8 : 38|8@0- (1.0,0.0) [-128.0|126.0] "" ECU
  SG_ sig_31_8 : 31|8@0+ (1.0,0.0) [0.0|254.0] "" ECU
  SG_ sig_39_8 : 39|8@1- (1.0000000000000006E-5,3.1622776601683794E-4) [-9.637722339831628E-4|0.0015762277660168386] "V" ECU

BO_ 1918 frame_1918: 5 Vector__XXX
  SG_ checksum_1_8 : 0|8@1+ (1.0,0.0) [0.0|255.0] "" ECU
  SG_ sig_9_12 : 9|12@1- (1.0000000000000007E-7,-3.1622776601683794E-4) [-5.210277660168381E-4|-1.1162776601683779E-4] "V" ECU
  SG_ sig_8_1 : 8|1@1+ (1.0,0.0) [0.0|1.0] "" ECU
  SG_ sig_23_15 : 23|15@1+ (1.0,0.0) [0.0|32766.0] "" ECU
  SG_ sig_21_2 : 21|2@1- (1.0,0.0) [-2.0|1.0] "" ECU
  SG_ sig_39_1 : 39|1@1+ (1.0,0.0) [0.0|1.0] "" ECU

BO_ 1614 frame_1614: 8 ECU
  SG_ checksum_1_8 : 7|8@0+ (1.0,0.0) [0.0|255.0] "" Vector__XXX
  SG_ sig_22_30 : 22|30@1- (1.0000000000000011E-10,0.0) [-0.05368709120000006|0.053687091000000055] "kWh" Vector__XXX
  SG_ sig_15_8 : 15|8@0- (1.0000000000000006E-6,-3.1622776601683795E-5) [-1.5962277660168386E-4|9.437722339831629E-5] "kWh" Vector__XXX
  SG_ sig_16_5 : 16|5@1- (1.0,0.0) [-16.0|14.0] "" Vector__XXX
  SG_ sig_21_1 : 21|1@1+ (1.0,0.0) [0.0|1.0] "" Vector__XXX
  SG_ sig_53_10 : 53|10@1- (0.010000000000000002,0.0) [-5.120000000000001|5.100000000000001] "kWh" Vector__XXX
  SG_ sig_52_1 : 52|1@1+ (1.0,0.0) [0.0|1.0] "" Vector__XXX

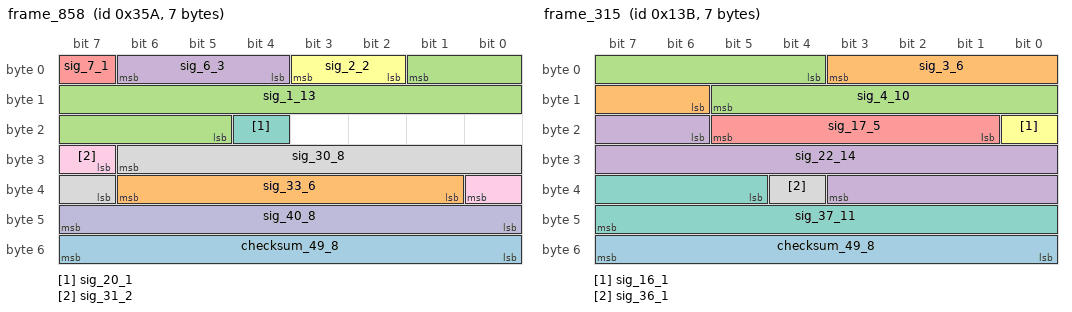
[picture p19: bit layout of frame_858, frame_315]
BO_ 858 frame_858: 7 Vector__XXX
  SG_ checksum_49_8 : 55|8@0+ (1.0,0.0) [0.0|255.0] "" ECU
  SG_ sig_33_6 : 33|6@1+ (100.0,3162.2776601683795) [3162.2776601683795|9362.27766016838] "kWh" ECU
  SG_ sig_1_13 : 1|13@0- (1.0000000000000007E-7,0.0) [-4.096000000000003E-4|4.094000000000003E-4] "km/h" ECU
  SG_ sig_6_3 : 6|3@0+ (1.0,0.0) [0.0|6.0] "" ECU
  SG_ sig_7_1 : 7|1@0+ (1.0,0.0) [0.0|1.0] "" ECU
  SG_ sig_2_2 : 2|2@1+ (1.0,0.0) [0.0|3.0] "" ECU
  SG_ sig_20_1 : 20|1@0+ (1.0,0.0) [0.0|1.0] "" ECU
  SG_ sig_30_8 : 30|8@0- (10.0,-316.22776601683796) [-1596.227766016838|943.7722339831621] "W" ECU
  SG_ sig_31_2 : 31|2@1- (1.0,0.0) [-2.0|1.0] "" ECU
  SG_ sig_40_8 : 40|8@1- (10.0,-316.22776601683796) [-1596.227766016838|943.7722339831621] "m/s^2" ECU

BO_ 467 frame_467: 6 Vector__XXX
  SG_ checksum_1_8 : 7|8@0+ (1.0,0.0) [0.0|255.0] "" ECU
  SG_ sig_24_16 : 24|16@1- (1.0000000000000006E-5,0.31622776601683794) [-0.011452233983162252|0.6438877660168381] "s" ECU
  SG_ sig_15_16 : 15|16@0- (1.0,-31622.776601683792) [-64390.77660168379|1143.2233983162077] "V" ECU
  SG_ sig_46_6 : 46|6@0- (1.0,0.0) [-32.0|30.0] "" ECU
  SG_ sig_40_1 : 40|1@1+ (1.0,0.0) [0.0|1.0] "" ECU
  SG_ sig_47_1 : 47|1@0+ (1.0,0.0) [0.0|1.0] "" ECU

BO_ 1754 frame_1754: 4 Vector__XXX
  SG_ checksum_25_8 : 24|8@1+ (1.0,0.0) [0.0|255.0] "" ECU
  SG_ sig_0_10 : 0|10@0+ (1.0,0.0) [0.0|1022.0] "" ECU
  SG_ sig_7_7 : 7|7@0- (1.0,-31.622776601683793) [-95.6227766016838|30.377223398316207] "W" ECU
  SG_ sig_18_5 : 18|5@1+ (1.0,0.0) [0.0|30.0] "" ECU

BO_ 923 frame_923: 7 Vector__XXX
  SG_ checksum_49_8 : 48|8@1+ (1.0,0.0) [0.0|255.0] "" ECU
  SG_ sig_14_18 : 14|18@1+ (1.0000000000000011E-10,-3.162277660168379E-6) [-3.162277660168379E-6|2.3051922339831647E-5] "s" ECU
  SG_ sig_0_13 : 0|13@1- (1.0,0.0) [-4096.0|4094.0] "" ECU
  SG_ sig_13_1 : 13|1@1+ (1.0,0.0) [0.0|1.0] "" ECU
  SG_ sig_32_14 : 32|14@1- (1.0,0.0) [-8192.0|8190.0] "" ECU
  SG_ sig_46_2 : 46|2@1- (1.0,0.0) [-2.0|1.0] "" ECU

BO_ 747 frame_747: 6 ECU
  SG_ checksum_41_8 : 47|8@0+ (1.0,0.0) [0.0|255.0] "" Vector__XXX
  SG_ sig_1_30 : 1|30@0- (1.0000000000000006E-6,316.22776601683796) [-220.64314598316236|853.0986760168382] "s" Vector__XXX
  SG_ sig_7_6 : 7|6@0+ (100.0,0.0) [0.0|6200.0] "m/s^2" Vector__XXX
  SG_ sig_35_1 : 35|1@0+ (1.0,0.0) [0.0|1.0] "" Vector__XXX
  SG_ sig_32_1 : 32|1@0+ (1.0,0.0) [0.0|1.0] "" Vector__XXX

BO_ 44 frame_44: 5 Vector__XXX
  SG_ checksum_33_8 : 39|8@0+ (1.0,0.0) [0.0|255.0] "" ECU
  SG_ sig_0_17 : 0|17@0+ (1.0000000000000006E-5,0.0) [0.0|1.3107000000000009] "m/s^2" ECU
  SG_ sig_7_7 : 7|7@0- (1.0,0.0) [-64.0|62.0] "" ECU
  SG_ sig_31_8 : 31|8@0+ (1.0,0.0) [0.0|254.0] "" ECU

BO_ 315 frame_315: 7 Vector__XXX
  SG_ checksum_49_8 : 48|8@1+ (1.0,0.0) [0.0|255.0] "" ECU
  SG_ sig_3_6 : 3|6@0+ (1.0000000000000006E-6,3.1622776601683795E-5) [3.1622776601683795E-5|9.362277660168383E-5] "m/s^2" ECU
  SG_ sig_4_10 : 4|10@1- (1.0000000000000007E-7,-3.1622776601683795E-5) [-8.282277660168384E-5|1.9377223398316245E-5] "A" ECU
  SG_ sig_22_14 : 22|14@1+ (0.1,316.22776601683796) [316.22776601683796|1954.427766016838] "kWh" ECU
  SG_ sig_17_5 : 17|5@1- (1.0,0.0) [-16.0|14.0] "" ECU
  SG_ sig_16_1 : 16|1@1+ (1.0,0.0) [0.0|1.0] "" ECU
  SG_ sig_37_11 : 37|11@1- (0.1,0.0) [-102.4|102.2] "kWh" ECU
  SG_ sig_36_1 : 36|1@0+ (1.0,0.0) [0.0|1.0] "" ECU

BO_ 1013 frame_1013: 2 ECU
  SG_ checksum_9_8 : 15|8@0+ (1.0,0.0) [0.0|255.0] "" Vector__XXX
  SG_ sig_4_5 : 4|5@0- (100.0,3162.2776601683795) [1562.2776601683795|4562.27766016838] "V" Vector__XXX
  SG_ sig_7_1 : 7|1@0+ (1.0,0.0) [0.0|1.0] "" Vector__XXX

BO_ 582 frame_582: 4 ECU
  SG_ checksum_9_8 : 15|8@0+ (1.0,0.0) [0.0|255.0] "" Vector__XXX
  SG_ sig_2_6 : 2|6@1- (1.0000000000000005E-4,-0.0031622776601683794) [-0.006362277660168381|-1.6227766016837803E-4] "kWh" Vector__XXX
  SG_ sig_0_2 : 0|2@1+ (1.0,0.0) [0.0|3.0] "" Vector__XXX
  SG_ sig_19_12 : 19|12@0+ (1.0000000000000006E-5,-0.03162277660168379) [-0.03162277660168379|0.009317223398316234] "km/h" Vector__XXX
  SG_ sig_23_4 : 23|4@0+ (0.010000000000000002,-0.03162277660168379) [-0.03162277660168379|0.10837722339831622] "s" Vector__XXX

BO_ 291 frame_291: 7 ECU
  SG_ checksum_33_8 : 32|8@1+ (1.0,0.0) [0.0|255.0] "" Vector__XXX
  SG_ sig_5_12 : 5|12@0- (1.0000000000000008E-8,3.1622776601683795E-5) [1.1142776601683778E-5|5.208277660168381E-5] "A" Vector__XXX
  SG_ sig_6_4 : 6|4@1- (1.0000000000000006E-6,-3.162277660168379E-6) [-1.1162277660168384E-5|2.8377223398316243E-6] "W" Vector__XXX
  SG_ sig_22_15 : 22|15@0+ (1.0000000000000006E-5,0.0) [0.0|0.3276600000000002] "W" Vector__XXX
  SG_ sig_41_8 : 41|8@1+ (1.0,0.0) [0.0|254.0] "" Vector__XXX
  SG_ sig_40_7 : 40|7@0+ (1000.0,-31622.776601683792) [-31622.776601683792|94377.22339831622] "s" Vector__XXX
  SG_ sig_49_1 : 49|1@1+ (1.0,0.0) [0.0|1.0] "" Vector__XXX

BO_ 137 frame_137: 6 ECU
  SG_ checksum_9_8 : 8|8@1+ (1.0,0.0) [0.0|255.0] "" Vector__XXX
  SG_ sig_2_6 : 2|6@1- (1.0000000000000006E-5,-3.1622776601683794E-4) [-6.362277660168381E-4|-1.622776601683775E-5] "V" Vector__XXX
  SG_ sig_0_2 : 0|2@1+ (1.0,0.0) [0.0|3.0] "" Vector__XXX
  SG_ sig_26_19 : 26|19@1+ (1.0,0.0) [0.0|524286.0] "" Vector__XXX
  SG_ sig_17_9 : 17|9@1+ (1.0,0.0) [0.0|510.0] "" Vector__XXX

CM_ BO_ 550 "Randomly defined CAN frame";
CM_ SG_ 550 checksum_41_8 "8 Bit checksum for protection of frame contents";
CM_ BO_ 794 "Randomly defined CAN frame";
CM_ SG_ 794 checksum_1_8 "8 Bit checksum for protection of frame contents";
CM_ BO_ 168 "Randomly defined CAN frame";
CM_ SG_ 168 checksum_41_8 "8 Bit checksum for protection of frame contents";
CM_ BO_ 66 "Randomly defined CAN frame";
CM_ SG_ 66 checksum_9_8 "8 Bit checksum for protection of frame contents";
CM_ BO_ 1387 "Randomly defined CAN frame";
CM_ SG_ 1387 checksum_17_8 "8 Bit checksum for protection of frame contents";
CM_ BO_ 1714 "Randomly defined CAN frame";
CM_ SG_ 1714 checksum_9_8 "8 Bit checksum for protection of frame contents";
CM_ BO_ 2010 "Randomly defined CAN frame";
CM_ SG_ 2010 checksum_41_8 "8 Bit checksum for protection of frame contents";
CM_ BO_ 300 "Randomly defined CAN frame";
CM_ SG_ 300 checksum_49_8 "8 Bit checksum for protection of frame contents";
CM_ BO_ 1561 "Randomly defined CAN frame";
CM_ SG_ 1561 checksum_9_8 "8 Bit checksum for protection of frame contents";
CM_ BO_ 992 "Randomly defined CAN frame";
CM_ SG_ 992 checksum_41_8 "8 Bit checksum for protection of frame contents";
CM_ BO_ 441 "Randomly defined CAN frame";
CM_ SG_ 441 checksum_9_8 "8 Bit checksum for protection of frame contents";
CM_ BO_ 1716 "Randomly defined CAN frame";
CM_ SG_ 1716 checksum_1_8 "8 Bit checksum for protection of frame contents";
CM_ BO_ 941 "Randomly defined CAN frame";
CM_ SG_ 941 checksum_25_8 "8 Bit checksum for protection of frame contents";
CM_ BO_ 157 "Randomly defined CAN frame";
CM_ SG_ 157 checksum_41_8 "8 Bit checksum for protection of frame contents";
CM_ BO_ 1981 "Randomly defined CAN frame";
CM_ SG_ 1981 checksum_41_8 "8 Bit checksum for protection of frame contents";
CM_ BO_ 1640 "Randomly defined CAN frame";
CM_ SG_ 1640 checksum_9_8 "8 Bit checksum for protection of frame contents";
CM_ BO_ 1575 "Randomly defined CAN frame";
CM_ SG_ 1575 checksum_57_8 "8 Bit checksum for protection of frame contents";
CM_ BO_ 1169 "Randomly defined CAN frame";
CM_ SG_ 1169 checksum_49_8 "8 Bit checksum for protection of frame contents";
CM_ BO_ 1941 "Randomly defined CAN frame";
CM_ SG_ 1941 checksum_33_8 "8 Bit checksum for protection of frame contents";
CM_ BO_ 978 "Randomly defined CAN frame";
CM_ SG_ 978 checksum_57_8 "8 Bit checksum for protection of frame contents";
CM_ BO_ 1155 "Randomly defined CAN frame";
CM_ SG_ 1155 checksum_1_8 "8 Bit checksum for protection of frame contents";
CM_ BO_ 1971 "Randomly defined CAN frame";
CM_ SG_ 1971 checksum_17_8 "8 Bit checksum for protection of frame contents";
CM_ BO_ 1838 "Randomly defined CAN frame";
CM_ SG_ 1838 checksum_41_8 "8 Bit checksum for protection of frame contents";
CM_ BO_ 1770 "Randomly defined CAN frame";
CM_ SG_ 1770 checksum_33_8 "8 Bit checksum for protection of frame contents";
CM_ BO_ 1701 "Randomly defined CAN frame";
CM_ SG_ 1701 checksum_25_8 "8 Bit checksum for protection of frame contents";
CM_ BO_ 1727 "Randomly defined CAN frame";
CM_ SG_ 1727 checksum_9_8 "8 Bit checksum for protection of frame contents";
CM_ BO_ 1329 "Randomly defined CAN frame";
CM_ SG_ 1329 checksum_17_8 "8 Bit checksum for protection of frame contents";
CM_ BO_ 1272 "Randomly defined CAN frame";
CM_ SG_ 1272 checksum_25_8 "8 Bit checksum for protection of frame contents";
CM_ BO_ 913 "Randomly defined CAN frame";
CM_ SG_ 913 checksum_33_8 "8 Bit checksum for protection of frame contents";
CM_ BO_ 1493 "Randomly defined CAN frame";
CM_ SG_ 1493 checksum_25_8 "8 Bit checksum for protection of frame contents";
CM_ BO_ 1165 "Randomly defined CAN frame";
CM_ SG_ 1165 checksum_17_8 "8 Bit checksum for protection of frame contents";
CM_ BO_ 997 "Randomly defined CAN frame";
CM_ SG_ 997 checksum_17_8 "8 Bit checksum for protection of frame contents";
CM_ BO_ 1269 "Randomly defined CAN frame";
CM_ SG_ 1269 checksum_1_8 "8 Bit checksum for protection of frame contents";
CM_ BO_ 1962 "Randomly defined CAN frame";
CM_ SG_ 1962 checksum_41_8 "8 Bit checksum for protection of frame contents";
CM_ BO_ 1116 "Randomly defined CAN frame";
CM_ SG_ 1116 checksum_41_8 "8 Bit checksum for protection of frame contents";
CM_ BO_ 32 "Randomly defined CAN frame";
CM_ SG_ 32 checksum_9_8 "8 Bit checksum for protection of frame contents";
CM_ BO_ 895 "Randomly defined CAN frame";
CM_ SG_ 895 checksum_9_8 "8 Bit checksum for protection of frame contents";
CM_ BO_ 1479 "Randomly defined CAN frame";
CM_ SG_ 1479 checksum_1_8 "8 Bit checksum for protection of frame contents";
CM_ BO_ 666 "Randomly defined CAN frame";
CM_ SG_ 666 checksum_9_8 "8 Bit checksum for protection of frame contents";
CM_ BO_ 557 "Randomly defined CAN frame";
CM_ SG_ 557 checksum_57_8 "8 Bit checksum for protection of frame contents";
CM_ BO_ 1857 "Randomly defined CAN frame";
CM_ SG_ 1857 checksum_1_8 "8 Bit checksum for protection of frame contents";
CM_ BO_ 1395 "Randomly defined CAN frame";
CM_ SG_ 1395 checksum_49_8 "8 Bit checksum for protection of frame contents";
CM_ BO_ 1495 "Randomly defined CAN frame";
CM_ SG_ 1495 checksum_49_8 "8 Bit checksum for protection of frame contents";
CM_ BO_ 457 "Randomly defined CAN frame";
CM_ SG_ 457 checksum_25_8 "8 Bit checksum for protection of frame contents";
CM_ BO_ 1175 "Randomly defined CAN frame";
CM_ SG_ 1175 checksum_1_8 "8 Bit checksum for protection of frame contents";
CM_ BO_ 1424 "Randomly defined CAN frame";
CM_ SG_ 1424 checksum_25_8 "8 Bit checksum for protection of frame contents";
CM_ BO_ 1859 "Randomly defined CAN frame";
CM_ SG_ 1859 checksum_17_8 "8 Bit checksum for protection of frame contents";
CM_ BO_ 985 "Randomly defined CAN frame";
CM_ SG_ 985 checksum_1_8 "8 Bit checksum for protection of frame contents";
CM_ BO_ 454 "Randomly defined CAN frame";
CM_ SG_ 454 checksum_49_8 "8 Bit checksum for protection of frame contents";
CM_ BO_ 753 "Randomly defined CAN frame";
CM_ SG_ 753 checksum_33_8 "8 Bit checksum for protection of frame contents";
CM_ BO_ 13 "Randomly defined CAN frame";
CM_ SG_ 13 checksum_41_8 "8 Bit checksum for protection of frame contents";
CM_ BO_ 1277 "Randomly defined CAN frame";
CM_ SG_ 1277 checksum_1_8 "8 Bit checksum for protection of frame contents";
CM_ BO_ 1593 "Randomly defined CAN frame";
CM_ SG_ 1593 checksum_9_8 "8 Bit checksum for protection of frame contents";
CM_ BO_ 1408 "Randomly defined CAN frame";
CM_ SG_ 1408 checksum_33_8 "8 Bit checksum for protection of frame contents";
CM_ BO_ 999 "Randomly defined CAN frame";
CM_ SG_ 999 checksum_25_8 "8 Bit checksum for protection of frame contents";
CM_ BO_ 132 "Randomly defined CAN frame";
CM_ SG_ 132 checksum_25_8 "8 Bit checksum for protection of frame contents";
CM_ BO_ 1980 "Randomly defined CAN frame";
CM_ SG_ 1980 checksum_17_8 "8 Bit checksum for protection of frame contents";
CM_ BO_ 553 "Randomly defined CAN frame";
CM_ SG_ 553 checksum_41_8 "8 Bit checksum for protection of frame contents";
CM_ BO_ 321 "Randomly defined CAN frame";
CM_ SG_ 321 checksum_25_8 "8 Bit checksum for protection of frame contents";
CM_ BO_ 1552 "Randomly defined CAN frame";
CM_ SG_ 1552 checksum_9_8 "8 Bit checksum for protection of frame contents";
CM_ BO_ 1287 "Randomly defined CAN frame";
CM_ SG_ 1287 checksum_17_8 "8 Bit checksum for protection of frame contents";
CM_ BO_ 1487 "Randomly defined CAN frame";
CM_ SG_ 1487 checksum_25_8 "8 Bit checksum for protection of frame contents";
CM_ BO_ 1225 "Randomly defined CAN frame";
CM_ SG_ 1225 checksum_1_8 "8 Bit checksum for protection of frame contents";
CM_ BO_ 1183 "Randomly defined CAN frame";
CM_ SG_ 1183 checksum_25_8 "8 Bit checksum for protection of frame contents";
CM_ BO_ 679 "Randomly defined CAN frame";
CM_ SG_ 679 checksum_9_8 "8 Bit checksum for protection of frame contents";
CM_ BO_ 257 "Randomly defined CAN frame";
CM_ SG_ 257 checksum_1_8 "8 Bit checksum for protection of frame contents";
CM_ BO_ 189 "Randomly defined CAN frame";
CM_ SG_ 189 checksum_9_8 "8 Bit checksum for protection of frame contents";
CM_ BO_ 494 "Randomly defined CAN frame";
CM_ SG_ 494 checksum_1_8 "8 Bit checksum for protection of frame contents";
CM_ BO_ 1045 "Randomly defined CAN frame";
CM_ SG_ 1045 checksum_17_8 "8 Bit checksum for protection of frame contents";
CM_ BO_ 1032 "Randomly defined CAN frame";
CM_ SG_ 1032 checksum_41_8 "8 Bit checksum for protection of frame contents";
CM_ BO_ 58 "Randomly defined CAN frame";
CM_ SG_ 58 checksum_9_8 "8 Bit checksum for protection of frame contents";
CM_ BO_ 313 "Randomly defined CAN frame";
CM_ SG_ 313 checksum_25_8 "8 Bit checksum for protection of frame contents";
CM_ BO_ 115 "Randomly defined CAN frame";
CM_ SG_ 115 checksum_9_8 "8 Bit checksum for protection of frame contents";
CM_ BO_ 1574 "Randomly defined CAN frame";
CM_ SG_ 1574 checksum_1_8 "8 Bit checksum for protection of frame contents";
CM_ BO_ 1757 "Randomly defined CAN frame";
CM_ SG_ 1757 checksum_41_8 "8 Bit checksum for protection of frame contents";
CM_ BO_ 1469 "Randomly defined CAN frame";
CM_ SG_ 1469 checksum_1_8 "8 Bit checksum for protection of frame contents";
CM_ BO_ 1684 "Randomly defined CAN frame";
CM_ SG_ 1684 checksum_49_8 "8 Bit checksum for protection of frame contents";
CM_ BO_ 505 "Randomly defined CAN frame";
CM_ SG_ 505 checksum_9_8 "8 Bit checksum for protection of frame contents";
CM_ BO_ 1310 "Randomly defined CAN frame";
CM_ SG_ 1310 checksum_17_8 "8 Bit checksum for protection of frame contents";
CM_ BO_ 567 "Randomly defined CAN frame";
CM_ SG_ 567 checksum_17_8 "8 Bit checksum for protection of frame contents";
CM_ BO_ 1632 "Randomly defined CAN frame";
CM_ SG_ 1632 checksum_17_8 "8 Bit checksum for protection of frame contents";
CM_ BO_ 345 "Randomly defined CAN frame";
CM_ SG_ 345 checksum_17_8 "8 Bit checksum for protection of frame contents";
CM_ BO_ 1918 "Randomly defined CAN frame";
CM_ SG_ 1918 checksum_1_8 "8 Bit checksum for protection of frame contents";
CM_ BO_ 1614 "Randomly defined CAN frame";
CM_ SG_ 1614 checksum_1_8 "8 Bit checksum for protection of frame contents";
CM_ BO_ 858 "Randomly defined CAN frame";
CM_ SG_ 858 checksum_49_8 "8 Bit checksum for protection of frame contents";
CM_ BO_ 467 "Randomly defined CAN frame";
CM_ SG_ 467 checksum_1_8 "8 Bit checksum for protection of frame contents";
CM_ BO_ 1754 "Randomly defined CAN frame";
CM_ SG_ 1754 checksum_25_8 "8 Bit checksum for protection of frame contents";
CM_ BO_ 923 "Randomly defined CAN frame";
CM_ SG_ 923 checksum_49_8 "8 Bit checksum for protection of frame contents";
CM_ BO_ 747 "Randomly defined CAN frame";
CM_ SG_ 747 checksum_41_8 "8 Bit checksum for protection of frame contents";
CM_ BO_ 44 "Randomly defined CAN frame";
CM_ SG_ 44 checksum_33_8 "8 Bit checksum for protection of frame contents";
CM_ BO_ 315 "Randomly defined CAN frame";
CM_ SG_ 315 checksum_49_8 "8 Bit checksum for protection of frame contents";
CM_ BO_ 1013 "Randomly defined CAN frame";
CM_ SG_ 1013 checksum_9_8 "8 Bit checksum for protection of frame contents";
CM_ BO_ 582 "Randomly defined CAN frame";
CM_ SG_ 582 checksum_9_8 "8 Bit checksum for protection of frame contents";
CM_ BO_ 291 "Randomly defined CAN frame";
CM_ SG_ 291 checksum_33_8 "8 Bit checksum for protection of frame contents";
CM_ BO_ 137 "Randomly defined CAN frame";
CM_ SG_ 137 checksum_9_8 "8 Bit checksum for protection of frame contents";
BA_DEF_ "Author" STRING;
BA_DEF_ BO_ "frameSendMode" ENUM  "regular","event","mixed";
BA_DEF_ BO_ "sendPeriod" INT 5 10000;
BA_DEF_ BO_ "crcStartValue" INT 1 255;
BA_DEF_ BO_ "eventMinDistance" INT 5 10000;
BA_DEF_ SG_ "initialValue" FLOAT -1e38 1e38;
BA_DEF_DEF_ "Author" "http://sourceforge.net/projects/comframe/";
BA_DEF_DEF_ "frameSendMode" "regular";
BA_DEF_DEF_ "sendPeriod" 10;
BA_DEF_DEF_ "crcStartValue" 1;
BA_DEF_DEF_ "eventMinDistance" 10;
BA_DEF_DEF_ "initialValue" 0.0;
BA_ "frameSendMode" BO_ 550 2;
BA_ "sendPeriod" BO_ 550 500;
BA_ "eventMinDistance" BO_ 550 100;
BA_ "crcStartValue" BO_ 550 155;
BA_ "initialValue" SG_ 550 sig_22_22 6.430560000000006E-4;
BA_ "initialValue" SG_ 550 sig_7_11 -12.062277660168382;
BA_ "initialValue" SG_ 550 sig_9_3 4.0;
BA_ "initialValue" SG_ 550 sig_11_2 1.0;
BA_ "sendPeriod" BO_ 794 1000;
BA_ "crcStartValue" BO_ 794 7;
BA_ "initialValue" SG_ 794 sig_10_17 0.3826500000000002;
BA_ "initialValue" SG_ 794 sig_27_9 -11.122776601683793;
BA_ "initialValue" SG_ 794 sig_45_11 8.282277660168383E-6;
BA_ "initialValue" SG_ 794 sig_36_9 139.0;
BA_ "sendPeriod" BO_ 168 20;
BA_ "crcStartValue" BO_ 168 248;
BA_ "initialValue" SG_ 168 sig_9_20 2.988420000000002;
BA_ "initialValue" SG_ 168 sig_1_8 -97.0;
BA_ "initialValue" SG_ 168 sig_29_7 0.009337722339831626;
BA_ "initialValue" SG_ 168 sig_36_4 0.07837722339831622;
BA_ "initialValue" SG_ 168 sig_48_6 -51622.77660168379;
BA_ "sendPeriod" BO_ 66 1000;
BA_ "crcStartValue" BO_ 66 127;
BA_ "initialValue" SG_ 66 sig_1_7 -3.9000000000000004;
BA_ "initialValue" SG_ 66 sig_21_7 437.7223398316205;
BA_ "initialValue" SG_ 66 sig_23_2 -1.0;
BA_ "initialValue" SG_ 66 sig_29_9 -2.0422776601683794;
BA_ "initialValue" SG_ 66 sig_32_3 -4.0;
BA_ "initialValue" SG_ 66 sig_47_15 3.3781776601683795E-6;
BA_ "initialValue" SG_ 66 sig_48_7 15.0;
BA_ "initialValue" SG_ 66 sig_57_2 1.0;
BA_ "sendPeriod" BO_ 1387 500;
BA_ "crcStartValue" BO_ 1387 163;
BA_ "initialValue" SG_ 1387 sig_0_14 11122.27766016838;
BA_ "initialValue" SG_ 1387 sig_14_2 1.0;
BA_ "initialValue" SG_ 1387 sig_29_14 2178.0;
BA_ "initialValue" SG_ 1387 sig_31_2 1.0;
BA_ "initialValue" SG_ 1387 sig_47_8 19262.27766016838;
BA_ "frameSendMode" BO_ 1714 2;
BA_ "sendPeriod" BO_ 1714 10000;
BA_ "eventMinDistance" BO_ 1714 100;
BA_ "crcStartValue" BO_ 1714 182;
BA_ "initialValue" SG_ 1714 sig_7_7 -61.0;
BA_ "initialValue" SG_ 1714 sig_0_1 1.0;
BA_ "initialValue" SG_ 1714 sig_16_26 8.286453860168383;
BA_ "initialValue" SG_ 1714 sig_47_6 4.900000000000003E-4;
BA_ "initialValue" SG_ 1714 sig_48_12 2250.0;
BA_ "initialValue" SG_ 1714 sig_62_3 2.0;
BA_ "initialValue" SG_ 1714 sig_63_1 1.0;
BA_ "sendPeriod" BO_ 2010 5;
BA_ "crcStartValue" BO_ 2010 56;
BA_ "initialValue" SG_ 2010 sig_23_5 4.26227766016838E-5;
BA_ "initialValue" SG_ 2010 sig_4_13 3.5442776601683796E-5;
BA_ "initialValue" SG_ 2010 sig_3_4 1300.0;
BA_ "initialValue" SG_ 2010 sig_22_6 766.2277660168379;
BA_ "initialValue" SG_ 2010 sig_31_6 -6.0;
BA_ "initialValue" SG_ 2010 sig_30_2 -1.0;
BA_ "initialValue" SG_ 2010 sig_39_3 -1.0;
BA_ "initialValue" SG_ 2010 sig_55_13 0.341627766016838;
BA_ "initialValue" SG_ 2010 sig_57_2 3.0;
BA_ "crcStartValue" BO_ 300 171;
BA_ "initialValue" SG_ 300 sig_12_20 249732.0;
BA_ "initialValue" SG_ 300 sig_6_8 2.2300000000000004;
BA_ "initialValue" SG_ 300 sig_14_2 2.0;
BA_ "initialValue" SG_ 300 sig_37_14 1700.727766016838;
BA_ "initialValue" SG_ 300 sig_24_3 -3.0;
BA_ "sendPeriod" BO_ 1561 10000;
BA_ "crcStartValue" BO_ 1561 149;
BA_ "initialValue" SG_ 1561 sig_7_8 -290.0;
BA_ "initialValue" SG_ 1561 sig_39_6 -11.0;
BA_ "initialValue" SG_ 1561 sig_17_11 343.0;
BA_ "initialValue" SG_ 1561 sig_16_1 1.0;
BA_ "initialValue" SG_ 1561 sig_30_4 -5.0;
BA_ "initialValue" SG_ 1561 sig_48_13 29.582776601683793;
BA_ "initialValue" SG_ 1561 sig_43_4 6162.27766016838;
BA_ "initialValue" SG_ 1561 sig_45_2 3.0;
BA_ "initialValue" SG_ 1561 sig_46_2 -2.0;
BA_ "frameSendMode" BO_ 992 1;
BA_ "eventMinDistance" BO_ 992 50;
BA_ "crcStartValue" BO_ 992 143;
BA_ "initialValue" SG_ 992 sig_3_26 415.34156016837824;
BA_ "initialValue" SG_ 992 sig_2_3 6.0;
BA_ "initialValue" SG_ 992 sig_31_2 1.0;
BA_ "initialValue" SG_ 992 sig_29_1 1.0;
BA_ "initialValue" SG_ 992 sig_32_8 4637.72233983162;
BA_ "initialValue" SG_ 992 sig_50_12 3247.0;
BA_ "initialValue" SG_ 992 sig_48_2 3.0;
BA_ "initialValue" SG_ 992 sig_63_2 -1.0;
BA_ "frameSendMode" BO_ 441 2;
BA_ "sendPeriod" BO_ 441 100;
BA_ "eventMinDistance" BO_ 441 100;
BA_ "crcStartValue" BO_ 441 244;
BA_ "initialValue" SG_ 441 sig_3_5 -18622.776601683792;
BA_ "initialValue" SG_ 441 sig_0_3 2.0;
BA_ "initialValue" SG_ 441 sig_19_11 0.11072277660168382;
BA_ "initialValue" SG_ 441 sig_16_3 1.0;
BA_ "initialValue" SG_ 441 sig_31_2 -1.0;
BA_ "initialValue" SG_ 441 sig_33_7 -0.02137722339831622;
BA_ "sendPeriod" BO_ 1716 100;
BA_ "crcStartValue" BO_ 1716 142;
BA_ "initialValue" SG_ 1716 sig_8_16 30325.223398316208;
BA_ "initialValue" SG_ 1716 sig_11_4 6.0;
BA_ "initialValue" SG_ 1716 sig_39_4 13.0;
BA_ "initialValue" SG_ 1716 sig_24_1 1.0;
BA_ "initialValue" SG_ 1716 sig_48_3 -1.0;
BA_ "initialValue" SG_ 1716 sig_56_7 62.0;
BA_ "sendPeriod" BO_ 941 500;
BA_ "crcStartValue" BO_ 941 118;
BA_ "initialValue" SG_ 941 sig_1_8 966.2277660168379;
BA_ "initialValue" SG_ 941 sig_9_10 0.4287722339831623;
BA_ "initialValue" SG_ 941 sig_38_19 -50612.676601683794;
BA_ "initialValue" SG_ 941 sig_51_3 5.0;
BA_ "initialValue" SG_ 941 sig_48_1 1.0;
BA_ "sendPeriod" BO_ 157 50;
BA_ "crcStartValue" BO_ 157 93;
BA_ "initialValue" SG_ 157 sig_14_26 -5.986254960168381;
BA_ "initialValue" SG_ 157 sig_7_9 71822.77660168378;
BA_ "initialValue" SG_ 157 sig_32_5 -0.1862277660168379;
BA_ "sendPeriod" BO_ 1981 25;
BA_ "crcStartValue" BO_ 1981 6;
BA_ "initialValue" SG_ 1981 sig_23_9 650.2277660168379;
BA_ "initialValue" SG_ 1981 sig_0_10 212.0;
BA_ "initialValue" SG_ 1981 sig_10_6 45.0;
BA_ "initialValue" SG_ 1981 sig_25_6 42.0;
BA_ "initialValue" SG_ 1981 sig_24_1 1.0;
BA_ "initialValue" SG_ 1981 sig_32_8 -85.0;
BA_ "initialValue" SG_ 1981 sig_54_8 -30.622776601683793;
BA_ "initialValue" SG_ 1981 sig_53_6 -0.0010622776601683782;
BA_ "initialValue" SG_ 1981 sig_63_2 3.0;
BA_ "sendPeriod" BO_ 1640 25;
BA_ "crcStartValue" BO_ 1640 205;
BA_ "initialValue" SG_ 1640 sig_7_7 100.0;
BA_ "initialValue" SG_ 1640 sig_0_1 1.0;
BA_ "initialValue" SG_ 1640 sig_30_5 15.0;
BA_ "initialValue" SG_ 1640 sig_22_7 5.2;
BA_ "initialValue" SG_ 1640 sig_23_1 1.0;
BA_ "initialValue" SG_ 1640 sig_31_1 1.0;
BA_ "initialValue" SG_ 1640 sig_25_4 3.0;
BA_ "initialValue" SG_ 1640 sig_54_7 58.0;
BA_ "sendPeriod" BO_ 1575 20;
BA_ "crcStartValue" BO_ 1575 250;
BA_ "initialValue" SG_ 1575 sig_31_17 -14684.223398316208;
BA_ "initialValue" SG_ 1575 sig_5_13 1172.0;
BA_ "initialValue" SG_ 1575 sig_22_4 8377.223398316208;
BA_ "initialValue" SG_ 1575 sig_18_1 1.0;
BA_ "initialValue" SG_ 1575 sig_44_10 750.2277660168379;
BA_ "initialValue" SG_ 1575 sig_45_2 -1.0;
BA_ "initialValue" SG_ 1575 sig_49_1 1.0;
BA_ "sendPeriod" BO_ 1169 20;
BA_ "crcStartValue" BO_ 1169 46;
BA_ "initialValue" SG_ 1169 sig_4_20 -54733.9766016838;
BA_ "initialValue" SG_ 1169 sig_5_2 -1.0;
BA_ "initialValue" SG_ 1169 sig_29_19 0.16552776601683786;
BA_ "initialValue" SG_ 1169 sig_31_2 1.0;
BA_ "initialValue" SG_ 1169 sig_56_7 0.005837722339831625;
BA_ "frameSendMode" BO_ 1941 2;
BA_ "sendPeriod" BO_ 1941 500;
BA_ "eventMinDistance" BO_ 1941 50;
BA_ "crcStartValue" BO_ 1941 27;
BA_ "initialValue" SG_ 1941 sig_16_3 1.0;
BA_ "initialValue" SG_ 1941 sig_15_9 -138.0;
BA_ "initialValue" SG_ 1941 sig_6_6 3000.0;
BA_ "initialValue" SG_ 1941 sig_0_1 1.0;
BA_ "initialValue" SG_ 1941 sig_19_4 -9.16227766016838;
BA_ "initialValue" SG_ 1941 sig_26_6 153.77223398316204;
BA_ "initialValue" SG_ 1941 sig_24_2 -1.0;
BA_ "initialValue" SG_ 1941 sig_45_10 -1.9300000000000015E-5;
BA_ "initialValue" SG_ 1941 sig_46_5 60.0;
BA_ "sendPeriod" BO_ 978 1000;
BA_ "crcStartValue" BO_ 978 206;
BA_ "initialValue" SG_ 978 sig_3_2 1.0;
BA_ "initialValue" SG_ 978 sig_6_3 -4.0;
BA_ "initialValue" SG_ 978 sig_7_1 1.0;
BA_ "initialValue" SG_ 978 sig_34_9 8.200000000000007E-7;
BA_ "initialValue" SG_ 978 sig_13_12 2713.0;
BA_ "initialValue" SG_ 978 sig_14_1 1.0;
BA_ "initialValue" SG_ 978 sig_16_13 0.2071277660168379;
BA_ "initialValue" SG_ 978 sig_55_7 -64.0;
BA_ "initialValue" SG_ 978 sig_41_2 3.0;
BA_ "sendPeriod" BO_ 1155 5;
BA_ "crcStartValue" BO_ 1155 232;
BA_ "initialValue" SG_ 1155 sig_19_19 403.512766016838;
BA_ "initialValue" SG_ 1155 sig_15_5 -4.3622776601683804E-4;
BA_ "initialValue" SG_ 1155 sig_8_3 6.0;
BA_ "initialValue" SG_ 1155 sig_16_3 2.0;
BA_ "initialValue" SG_ 1155 sig_39_1 1.0;
BA_ "initialValue" SG_ 1155 sig_38_1 1.0;
BA_ "sendPeriod" BO_ 1971 500;
BA_ "crcStartValue" BO_ 1971 59;
BA_ "initialValue" SG_ 1971 sig_0_15 -1495.5776601683795;
BA_ "initialValue" SG_ 1971 sig_15_1 1.0;
BA_ "initialValue" SG_ 1971 sig_25_7 5.600000000000004E-6;
BA_ "crcStartValue" BO_ 1838 9;
BA_ "initialValue" SG_ 1838 sig_12_20 6.716257660168383E-6;
BA_ "initialValue" SG_ 1838 sig_7_7 0.002437722339831623;
BA_ "initialValue" SG_ 1838 sig_32_5 16.0;
BA_ "initialValue" SG_ 1838 sig_38_2 -1.0;
BA_ "initialValue" SG_ 1838 sig_49_7 38.0;
BA_ "sendPeriod" BO_ 1770 50;
BA_ "crcStartValue" BO_ 1770 55;
BA_ "initialValue" SG_ 1770 sig_11_17 7128.72233983162;
BA_ "initialValue" SG_ 1770 sig_0_3 1.0;
BA_ "initialValue" SG_ 1770 sig_13_2 3.0;
BA_ "initialValue" SG_ 1770 sig_24_3 -2.0;
BA_ "sendPeriod" BO_ 1701 50;
BA_ "crcStartValue" BO_ 1701 143;
BA_ "initialValue" SG_ 1701 sig_5_20 571564.0;
BA_ "initialValue" SG_ 1701 sig_16_2 2.0;
BA_ "initialValue" SG_ 1701 sig_33_16 2.853077660168379E-4;
BA_ "initialValue" SG_ 1701 sig_38_5 3.0;
BA_ "initialValue" SG_ 1701 sig_39_1 1.0;
BA_ "initialValue" SG_ 1701 sig_63_7 83000.0;
BA_ "initialValue" SG_ 1701 sig_56_1 1.0;
BA_ "sendPeriod" BO_ 1727 25;
BA_ "crcStartValue" BO_ 1727 248;
BA_ "initialValue" SG_ 1727 sig_7_7 68.0;
BA_ "initialValue" SG_ 1727 sig_0_1 1.0;
BA_ "initialValue" SG_ 1727 sig_22_6 3900.0;
BA_ "initialValue" SG_ 1727 sig_17_5 0.00456227766016838;
BA_ "initialValue" SG_ 1727 sig_31_4 -81622.77660168378;
BA_ "initialValue" SG_ 1727 sig_16_1 1.0;
BA_ "frameSendMode" BO_ 1329 2;
BA_ "sendPeriod" BO_ 1329 1000;
BA_ "eventMinDistance" BO_ 1329 50;
BA_ "crcStartValue" BO_ 1329 233;
BA_ "initialValue" SG_ 1329 sig_2_11 6.730000000000001;
BA_ "initialValue" SG_ 1329 sig_3_5 220.0;
BA_ "initialValue" SG_ 1329 sig_24_7 8.33772233983163E-6;
BA_ "sendPeriod" BO_ 1272 25;
BA_ "crcStartValue" BO_ 1272 241;
BA_ "initialValue" SG_ 1272 sig_4_12 -1.4800000000000013E-6;
BA_ "initialValue" SG_ 1272 sig_2_3 2.0;
BA_ "initialValue" SG_ 1272 sig_23_8 -0.0010662277660168384;
BA_ "initialValue" SG_ 1272 sig_36_12 8.000000000000005E-4;
BA_ "initialValue" SG_ 1272 sig_37_4 -3.0;
BA_ "frameSendMode" BO_ 913 2;
BA_ "sendPeriod" BO_ 913 10000;
BA_ "eventMinDistance" BO_ 913 1000;
BA_ "crcStartValue" BO_ 913 144;
BA_ "initialValue" SG_ 913 sig_8_18 171497.0;
BA_ "initialValue" SG_ 913 sig_7_5 -4.000000000000003E-7;
BA_ "initialValue" SG_ 913 sig_2_3 -3.0;
BA_ "initialValue" SG_ 913 sig_27_5 40.622776601683796;
BA_ "initialValue" SG_ 913 sig_47_10 36.0;
BA_ "initialValue" SG_ 913 sig_48_5 -1.7622776601683784E-4;
BA_ "initialValue" SG_ 913 sig_53_1 1.0;
BA_ "frameSendMode" BO_ 1493 2;
BA_ "sendPeriod" BO_ 1493 10000;
BA_ "eventMinDistance" BO_ 1493 100;
BA_ "crcStartValue" BO_ 1493 230;
BA_ "initialValue" SG_ 1493 sig_11_9 -56.0;
BA_ "initialValue" SG_ 1493 sig_1_9 5.8422776601683817E-5;
BA_ "initialValue" SG_ 1493 sig_47_9 160.0;
BA_ "initialValue" SG_ 1493 sig_36_6 1.0000000000000006E-5;
BA_ "initialValue" SG_ 1493 sig_42_5 -4.0;
BA_ "initialValue" SG_ 1493 sig_58_6 280.0;
BA_ "sendPeriod" BO_ 1165 5;
BA_ "crcStartValue" BO_ 1165 148;
BA_ "initialValue" SG_ 1165 sig_6_14 89.17223398316207;
BA_ "initialValue" SG_ 1165 sig_7_1 1.0;
BA_ "initialValue" SG_ 1165 sig_8_1 1.0;
BA_ "initialValue" SG_ 1165 sig_24_1 1.0;
BA_ "frameSendMode" BO_ 997 1;
BA_ "eventMinDistance" BO_ 997 1000;
BA_ "crcStartValue" BO_ 997 251;
BA_ "initialValue" SG_ 997 sig_0_16 3832.9776601683798;
BA_ "initialValue" SG_ 997 sig_38_14 0.06824277660168382;
BA_ "initialValue" SG_ 997 sig_25_6 -0.002562277660168379;
BA_ "initialValue" SG_ 997 sig_39_1 1.0;
BA_ "initialValue" SG_ 997 sig_40_1 1.0;
BA_ "sendPeriod" BO_ 1269 50;
BA_ "crcStartValue" BO_ 1269 49;
BA_ "initialValue" SG_ 1269 sig_25_33 52.86525383162234;
BA_ "initialValue" SG_ 1269 sig_14_8 9.937722339831631E-6;
BA_ "initialValue" SG_ 1269 sig_17_5 17.0;
BA_ "initialValue" SG_ 1269 sig_24_1 1.0;
BA_ "initialValue" SG_ 1269 sig_60_4 -383.77223398316204;
BA_ "initialValue" SG_ 1269 sig_59_2 2.0;
BA_ "sendPeriod" BO_ 1962 500;
BA_ "crcStartValue" BO_ 1962 102;
BA_ "initialValue" SG_ 1962 sig_19_21 2.3114807660168402E-5;
BA_ "initialValue" SG_ 1962 sig_5_10 10582.27766016838;
BA_ "initialValue" SG_ 1962 sig_4_5 16.0;
BA_ "initialValue" SG_ 1962 sig_15_1 1.0;
BA_ "initialValue" SG_ 1962 sig_50_12 -0.34282776601683795;
BA_ "initialValue" SG_ 1962 sig_49_3 3.0;
BA_ "frameSendMode" BO_ 1116 2;
BA_ "sendPeriod" BO_ 1116 100;
BA_ "eventMinDistance" BO_ 1116 100;
BA_ "crcStartValue" BO_ 1116 175;
BA_ "initialValue" SG_ 1116 sig_28_6 -39.622776601683796;
BA_ "initialValue" SG_ 1116 sig_12_16 0.06688000000000004;
BA_ "initialValue" SG_ 1116 sig_2_6 -0.566227766016838;
BA_ "initialValue" SG_ 1116 sig_15_3 6.0;
BA_ "initialValue" SG_ 1116 sig_33_5 -2.0;
BA_ "initialValue" SG_ 1116 sig_32_1 1.0;
BA_ "frameSendMode" BO_ 32 2;
BA_ "sendPeriod" BO_ 32 500;
BA_ "eventMinDistance" BO_ 32 100;
BA_ "crcStartValue" BO_ 32 29;
BA_ "initialValue" SG_ 32 sig_0_8 12.0;
BA_ "initialValue" SG_ 32 sig_20_11 -2020.0;
BA_ "initialValue" SG_ 32 sig_16_3 -1.0;
BA_ "initialValue" SG_ 32 sig_19_1 1.0;
BA_ "initialValue" SG_ 32 sig_32_12 -861.0;
BA_ "initialValue" SG_ 32 sig_31_1 1.0;
BA_ "initialValue" SG_ 32 sig_44_4 6000.0;
BA_ "crcStartValue" BO_ 895 88;
BA_ "initialValue" SG_ 895 sig_0_5 0.011000000000000003;
BA_ "initialValue" SG_ 895 sig_7_3 6.0;
BA_ "initialValue" SG_ 895 sig_22_7 88.0;
BA_ "initialValue" SG_ 895 sig_23_1 1.0;
BA_ "frameSendMode" BO_ 1479 1;
BA_ "eventMinDistance" BO_ 1479 1000;
BA_ "crcStartValue" BO_ 1479 58;
BA_ "initialValue" SG_ 1479 sig_23_9 382.0;
BA_ "initialValue" SG_ 1479 sig_8_8 219.0;
BA_ "initialValue" SG_ 1479 sig_27_12 1477.0;
BA_ "initialValue" SG_ 1479 sig_28_1 1.0;
BA_ "sendPeriod" BO_ 666 10000;
BA_ "crcStartValue" BO_ 666 38;
BA_ "initialValue" SG_ 666 sig_4_5 300.0;
BA_ "initialValue" SG_ 666 sig_5_2 -2.0;
BA_ "initialValue" SG_ 666 sig_23_7 -0.05000000000000001;
BA_ "initialValue" SG_ 666 sig_16_1 1.0;
BA_ "frameSendMode" BO_ 557 2;
BA_ "sendPeriod" BO_ 557 1000;
BA_ "eventMinDistance" BO_ 557 1000;
BA_ "crcStartValue" BO_ 557 126;
BA_ "initialValue" SG_ 557 sig_24_27 0.03632345539831627;
BA_ "initialValue" SG_ 557 sig_6_8 138.0;
BA_ "initialValue" SG_ 557 sig_0_6 6062.27766016838;
BA_ "initialValue" SG_ 557 sig_15_8 90.0;
BA_ "initialValue" SG_ 557 sig_14_1 1.0;
BA_ "initialValue" SG_ 557 sig_52_4 -0.002162277660168379;
BA_ "initialValue" SG_ 557 sig_51_1 1.0;
BA_ "frameSendMode" BO_ 1857 2;
BA_ "sendPeriod" BO_ 1857 1000;
BA_ "eventMinDistance" BO_ 1857 500;
BA_ "crcStartValue" BO_ 1857 104;
BA_ "initialValue" SG_ 1857 sig_21_16 -0.32356776601683795;
BA_ "initialValue" SG_ 1857 sig_15_10 129.7227766016838;
BA_ "initialValue" SG_ 1857 sig_37_5 6000.0;
BA_ "sendPeriod" BO_ 1395 50;
BA_ "crcStartValue" BO_ 1395 151;
BA_ "initialValue" SG_ 1395 sig_27_15 -9.041776601683778E-4;
BA_ "initialValue" SG_ 1395 sig_7_8 10.0;
BA_ "initialValue" SG_ 1395 sig_5_5 -0.00406227766016838;
BA_ "initialValue" SG_ 1395 sig_15_9 0.06812277660168381;
BA_ "initialValue" SG_ 1395 sig_42_3 4.0;
BA_ "initialValue" SG_ 1395 sig_44_2 -1.0;
BA_ "frameSendMode" BO_ 1495 2;
BA_ "sendPeriod" BO_ 1495 1000;
BA_ "eventMinDistance" BO_ 1495 500;
BA_ "crcStartValue" BO_ 1495 18;
BA_ "initialValue" SG_ 1495 sig_13_20 -0.7925437660168382;
BA_ "initialValue" SG_ 1495 sig_7_8 -1062.2776601683795;
BA_ "initialValue" SG_ 1495 sig_15_2 -2.0;
BA_ "initialValue" SG_ 1495 sig_34_6 24.0;
BA_ "initialValue" SG_ 1495 sig_38_4 2.8377223398316205;
BA_ "initialValue" SG_ 1495 sig_62_7 9162.27766016838;
BA_ "sendPeriod" BO_ 457 100;
BA_ "crcStartValue" BO_ 457 53;
BA_ "initialValue" SG_ 457 sig_13_10 0.33222776601683796;
BA_ "initialValue" SG_ 457 sig_1_10 -284.0;
BA_ "initialValue" SG_ 457 sig_11_2 -2.0;
BA_ "initialValue" SG_ 457 sig_23_1 1.0;
BA_ "sendPeriod" BO_ 1175 50;
BA_ "crcStartValue" BO_ 1175 155;
BA_ "initialValue" SG_ 1175 sig_13_12 189.42776601683795;
BA_ "initialValue" SG_ 1175 sig_8_4 -0.816227766016838;
BA_ "initialValue" SG_ 1175 sig_12_1 1.0;
BA_ "initialValue" SG_ 1175 sig_25_12 31.0;
BA_ "initialValue" SG_ 1175 sig_37_3 2.0;
BA_ "frameSendMode" BO_ 1424 2;
BA_ "sendPeriod" BO_ 1424 10000;
BA_ "eventMinDistance" BO_ 1424 500;
BA_ "crcStartValue" BO_ 1424 154;
BA_ "initialValue" SG_ 1424 sig_2_12 185.0;
BA_ "initialValue" SG_ 1424 sig_4_4 1.1000000000000006E-5;
BA_ "initialValue" SG_ 1424 sig_3_1 1.0;
BA_ "initialValue" SG_ 1424 sig_18_5 3.6622776601683796E-4;
BA_ "initialValue" SG_ 1424 sig_36_20 208848.0;
BA_ "frameSendMode" BO_ 1859 2;
BA_ "sendPeriod" BO_ 1859 500;
BA_ "eventMinDistance" BO_ 1859 50;
BA_ "crcStartValue" BO_ 1859 87;
BA_ "initialValue" SG_ 1859 sig_5_11 -847.0;
BA_ "initialValue" SG_ 1859 sig_1_4 4.0;
BA_ "initialValue" SG_ 1859 sig_0_1 1.0;
BA_ "initialValue" SG_ 1859 sig_28_8 0.016562277660168385;
BA_ "initialValue" SG_ 1859 sig_27_7 -1.0;
BA_ "initialValue" SG_ 1859 sig_36_1 1.0;
BA_ "initialValue" SG_ 1859 sig_52_12 419.22776601683796;
BA_ "initialValue" SG_ 1859 sig_44_8 810.0;
BA_ "initialValue" SG_ 1859 sig_56_1 1.0;
BA_ "sendPeriod" BO_ 985 100;
BA_ "crcStartValue" BO_ 985 145;
BA_ "initialValue" SG_ 985 sig_20_16 4085.2776601683795;
BA_ "initialValue" SG_ 985 sig_12_8 77377.22339831622;
BA_ "initialValue" SG_ 985 sig_11_3 3.0;
BA_ "initialValue" SG_ 985 sig_8_1 1.0;
BA_ "initialValue" SG_ 985 sig_63_4 1.0000000000000006E-4;
BA_ "frameSendMode" BO_ 454 2;
BA_ "sendPeriod" BO_ 454 1000;
BA_ "eventMinDistance" BO_ 454 1000;
BA_ "crcStartValue" BO_ 454 245;
BA_ "initialValue" SG_ 454 sig_16_26 6.604671560168384E-5;
BA_ "initialValue" SG_ 454 sig_13_4 -2.8377223398316233E-4;
BA_ "initialValue" SG_ 454 sig_0_10 -0.0041100000000000025;
BA_ "initialValue" SG_ 454 sig_15_2 1.0;
BA_ "initialValue" SG_ 454 sig_47_6 40.0;
BA_ "frameSendMode" BO_ 753 2;
BA_ "sendPeriod" BO_ 753 500;
BA_ "eventMinDistance" BO_ 753 500;
BA_ "crcStartValue" BO_ 753 117;
BA_ "initialValue" SG_ 753 sig_5_16 922.2277660168381;
BA_ "initialValue" SG_ 753 sig_20_13 -7.223398316232206E-8;
BA_ "sendPeriod" BO_ 13 5;
BA_ "crcStartValue" BO_ 13 30;
BA_ "initialValue" SG_ 13 sig_31_4 -7.0;
BA_ "initialValue" SG_ 13 sig_2_14 119.91722339831622;
BA_ "initialValue" SG_ 13 sig_0_2 3.0;
BA_ "initialValue" SG_ 13 sig_19_12 -0.016892776601683784;
BA_ "initialValue" SG_ 13 sig_35_5 -1362.2776601683795;
BA_ "initialValue" SG_ 13 sig_48_8 0.001770000000000001;
BA_ "sendPeriod" BO_ 1277 10000;
BA_ "crcStartValue" BO_ 1277 153;
BA_ "initialValue" SG_ 1277 sig_15_5 1.0000000000000005E-4;
BA_ "initialValue" SG_ 1277 sig_10_3 2.0;
BA_ "sendPeriod" BO_ 1593 5;
BA_ "crcStartValue" BO_ 1593 191;
BA_ "initialValue" SG_ 1593 sig_3_5 -0.0762277660168379;
BA_ "initialValue" SG_ 1593 sig_0_3 6.0;
BA_ "initialValue" SG_ 1593 sig_19_18 197832.0;
BA_ "initialValue" SG_ 1593 sig_33_2 -2.0;
BA_ "sendPeriod" BO_ 1408 500;
BA_ "crcStartValue" BO_ 1408 10;
BA_ "initialValue" SG_ 1408 sig_20_8 -108.0;
BA_ "initialValue" SG_ 1408 sig_5_17 -35948.0;
BA_ "initialValue" SG_ 1408 sig_28_2 -2.0;
BA_ "initialValue" SG_ 1408 sig_47_11 -945.0;
BA_ "initialValue" SG_ 1408 sig_52_5 -0.22622776601683792;
BA_ "sendPeriod" BO_ 999 500;
BA_ "crcStartValue" BO_ 999 2;
BA_ "initialValue" SG_ 999 sig_4_10 0.29777223398316216;
BA_ "initialValue" SG_ 999 sig_3_6 -31.0;
BA_ "initialValue" SG_ 999 sig_23_6 52622.77660168379;
BA_ "initialValue" SG_ 999 sig_16_2 1.0;
BA_ "initialValue" SG_ 999 sig_33_14 -4.601722339831623;
BA_ "initialValue" SG_ 999 sig_39_6 1200.0;
BA_ "sendPeriod" BO_ 132 500;
BA_ "crcStartValue" BO_ 132 122;
BA_ "initialValue" SG_ 132 sig_1_9 -3.6522776601683796E-6;
BA_ "initialValue" SG_ 132 sig_0_1 1.0;
BA_ "initialValue" SG_ 132 sig_11_12 0.2873277660168379;
BA_ "initialValue" SG_ 132 sig_10_1 1.0;
BA_ "initialValue" SG_ 132 sig_33_15 -12228.0;
BA_ "initialValue" SG_ 132 sig_32_1 1.0;
BA_ "sendPeriod" BO_ 1980 20;
BA_ "crcStartValue" BO_ 1980 139;
BA_ "initialValue" SG_ 1980 sig_7_13 -0.00451727766016838;
BA_ "initialValue" SG_ 1980 sig_10_3 2.0;
BA_ "initialValue" SG_ 1980 sig_24_2 -2.0;
BA_ "initialValue" SG_ 1980 sig_31_1 1.0;
BA_ "initialValue" SG_ 1980 sig_42_13 3.5180000000000026E-4;
BA_ "initialValue" SG_ 1980 sig_39_8 0.12600000000000003;
BA_ "initialValue" SG_ 1980 sig_55_1 1.0;
BA_ "sendPeriod" BO_ 553 1000;
BA_ "crcStartValue" BO_ 553 204;
BA_ "initialValue" SG_ 553 sig_1_12 0.014062776601683782;
BA_ "initialValue" SG_ 553 sig_7_6 4.000000000000002E-4;
BA_ "initialValue" SG_ 553 sig_31_14 -1336.0;
BA_ "initialValue" SG_ 553 sig_21_5 0.0031622776601683794;
BA_ "initialValue" SG_ 553 sig_33_2 3.0;
BA_ "sendPeriod" BO_ 321 500;
BA_ "crcStartValue" BO_ 321 160;
BA_ "initialValue" SG_ 321 sig_14_9 -184.0;
BA_ "initialValue" SG_ 321 sig_1_11 1.9022776601683793;
BA_ "initialValue" SG_ 321 sig_0_1 1.0;
BA_ "initialValue" SG_ 321 sig_12_2 1.0;
BA_ "initialValue" SG_ 321 sig_33_2 -2.0;
BA_ "initialValue" SG_ 321 sig_35_5 35622.77660168379;
BA_ "sendPeriod" BO_ 1552 50;
BA_ "crcStartValue" BO_ 1552 228;
BA_ "initialValue" SG_ 1552 sig_0_8 14.0;
BA_ "initialValue" SG_ 1552 sig_23_12 208.0;
BA_ "initialValue" SG_ 1552 sig_24_4 2837.7223398316205;
BA_ "frameSendMode" BO_ 1287 2;
BA_ "sendPeriod" BO_ 1287 1000;
BA_ "eventMinDistance" BO_ 1287 500;
BA_ "crcStartValue" BO_ 1287 36;
BA_ "initialValue" SG_ 1287 sig_1_14 0.10914277660168384;
BA_ "initialValue" SG_ 1287 sig_15_1 1.0;
BA_ "initialValue" SG_ 1287 sig_24_11 -8.392277660168384E-5;
BA_ "initialValue" SG_ 1287 sig_46_13 525.427766016838;
BA_ "initialValue" SG_ 1287 sig_36_10 3.0622776601683794;
BA_ "initialValue" SG_ 1287 sig_35_1 1.0;
BA_ "initialValue" SG_ 1287 sig_59_4 5.000000000000003E-5;
BA_ "sendPeriod" BO_ 1487 50;
BA_ "crcStartValue" BO_ 1487 2;
BA_ "initialValue" SG_ 1487 sig_0_7 10000.0;
BA_ "initialValue" SG_ 1487 sig_11_13 -1.170000000000001E-6;
BA_ "initialValue" SG_ 1487 sig_32_7 376.22776601683796;
BA_ "frameSendMode" BO_ 1225 2;
BA_ "sendPeriod" BO_ 1225 1000;
BA_ "eventMinDistance" BO_ 1225 100;
BA_ "crcStartValue" BO_ 1225 85;
BA_ "initialValue" SG_ 1225 sig_16_7 0.09200000000000003;
BA_ "initialValue" SG_ 1225 sig_11_10 9.177223398316212;
BA_ "initialValue" SG_ 1225 sig_14_3 -1.0;
BA_ "initialValue" SG_ 1225 sig_15_1 1.0;
BA_ "initialValue" SG_ 1225 sig_24_2 2.0;
BA_ "crcStartValue" BO_ 1183 154;
BA_ "initialValue" SG_ 1183 sig_12_11 993.0;
BA_ "initialValue" SG_ 1183 sig_4_6 0.02162277660168379;
BA_ "initialValue" SG_ 1183 sig_1_3 5.0;
BA_ "initialValue" SG_ 1183 sig_10_2 2.0;
BA_ "initialValue" SG_ 1183 sig_46_3 2.0;
BA_ "initialValue" SG_ 1183 sig_38_7 8.0;
BA_ "initialValue" SG_ 1183 sig_35_3 1.0;
BA_ "initialValue" SG_ 1183 sig_33_2 2.0;
BA_ "initialValue" SG_ 1183 sig_45_1 1.0;
BA_ "initialValue" SG_ 1183 sig_49_12 4.12027766016838E-6;
BA_ "initialValue" SG_ 1183 sig_61_3 1.0;
BA_ "sendPeriod" BO_ 679 5;
BA_ "crcStartValue" BO_ 679 144;
BA_ "initialValue" SG_ 679 sig_7_8 1.4662277660168381;
BA_ "initialValue" SG_ 679 sig_22_10 347.0;
BA_ "initialValue" SG_ 679 sig_24_4 1.0;
BA_ "initialValue" SG_ 679 sig_32_8 -1226.227766016838;
BA_ "sendPeriod" BO_ 257 10000;
BA_ "crcStartValue" BO_ 257 48;
BA_ "initialValue" SG_ 257 sig_13_21 -4.662670000000003;
BA_ "initialValue" SG_ 257 sig_37_6 19.0;
BA_ "initialValue" SG_ 257 sig_24_3 -2.0;
BA_ "sendPeriod" BO_ 189 10000;
BA_ "crcStartValue" BO_ 189 37;
BA_ "initialValue" SG_ 189 sig_7_7 276.22776601683796;
BA_ "initialValue" SG_ 189 sig_0_1 1.0;
BA_ "sendPeriod" BO_ 494 50;
BA_ "crcStartValue" BO_ 494 151;
BA_ "initialValue" SG_ 494 sig_8_11 718.0;
BA_ "initialValue" SG_ 494 sig_20_16 11170.0;
BA_ "initialValue" SG_ 494 sig_19_1 1.0;
BA_ "initialValue" SG_ 494 sig_39_4 -516.2277660168379;
BA_ "sendPeriod" BO_ 1045 5;
BA_ "crcStartValue" BO_ 1045 152;
BA_ "initialValue" SG_ 1045 sig_0_16 56432.0;
BA_ "initialValue" SG_ 1045 sig_29_5 0.002600000000000001;
BA_ "initialValue" SG_ 1045 sig_31_2 3.0;
BA_ "sendPeriod" BO_ 1032 1000;
BA_ "crcStartValue" BO_ 1032 25;
BA_ "initialValue" SG_ 1032 sig_2_25 5782.84166016838;
BA_ "initialValue" SG_ 1032 sig_28_11 -9.262277660168381;
BA_ "initialValue" SG_ 1032 sig_39_1 1.0;
BA_ "initialValue" SG_ 1032 sig_48_6 -13.0;
BA_ "initialValue" SG_ 1032 sig_54_2 1.0;
BA_ "sendPeriod" BO_ 58 100;
BA_ "crcStartValue" BO_ 58 132;
BA_ "initialValue" SG_ 58 sig_6_7 3062.2776601683795;
BA_ "initialValue" SG_ 58 sig_7_1 1.0;
BA_ "initialValue" SG_ 58 sig_20_3 3.0;
BA_ "initialValue" SG_ 58 sig_23_1 1.0;
BA_ "initialValue" SG_ 58 sig_19_4 0.21622776601683794;
BA_ "sendPeriod" BO_ 313 100;
BA_ "crcStartValue" BO_ 313 235;
BA_ "initialValue" SG_ 313 sig_6_7 35.0;
BA_ "initialValue" SG_ 313 sig_0_6 -17.0;
BA_ "initialValue" SG_ 313 sig_14_9 2.1300000000000003;
BA_ "initialValue" SG_ 313 sig_13_1 1.0;
BA_ "crcStartValue" BO_ 115 52;
BA_ "initialValue" SG_ 115 sig_0_8 0.050622776601683794;
BA_ "initialValue" SG_ 115 sig_17_14 -0.2098722339831623;
BA_ "initialValue" SG_ 115 sig_16_1 1.0;
BA_ "crcStartValue" BO_ 1574 179;
BA_ "initialValue" SG_ 1574 sig_21_12 3646.0;
BA_ "initialValue" SG_ 1574 sig_15_10 313.0;
BA_ "initialValue" SG_ 1574 sig_24_2 3.0;
BA_ "initialValue" SG_ 1574 sig_32_1 1.0;
BA_ "sendPeriod" BO_ 1757 5;
BA_ "crcStartValue" BO_ 1757 142;
BA_ "initialValue" SG_ 1757 sig_26_11 -3.070000000000002E-5;
BA_ "initialValue" SG_ 1757 sig_2_10 1.510000000000001E-4;
BA_ "initialValue" SG_ 1757 sig_0_2 3.0;
BA_ "initialValue" SG_ 1757 sig_12_2 3.0;
BA_ "initialValue" SG_ 1757 sig_23_6 33.0;
BA_ "initialValue" SG_ 1757 sig_17_1 1.0;
BA_ "initialValue" SG_ 1757 sig_37_2 -1.0;
BA_ "initialValue" SG_ 1757 sig_39_1 1.0;
BA_ "sendPeriod" BO_ 1469 20;
BA_ "crcStartValue" BO_ 1469 111;
BA_ "initialValue" SG_ 1469 sig_36_14 9.490000000000009E-7;
BA_ "initialValue" SG_ 1469 sig_23_18 67560.0;
BA_ "initialValue" SG_ 1469 sig_14_7 9.700000000000007E-6;
BA_ "initialValue" SG_ 1469 sig_48_7 0.04662277660168379;
BA_ "initialValue" SG_ 1469 sig_61_4 9.0;
BA_ "frameSendMode" BO_ 1684 2;
BA_ "sendPeriod" BO_ 1684 1000;
BA_ "eventMinDistance" BO_ 1684 1000;
BA_ "crcStartValue" BO_ 1684 248;
BA_ "initialValue" SG_ 1684 sig_12_33 0.004301927020168381;
BA_ "initialValue" SG_ 1684 sig_7_4 8837.72233983162;
BA_ "initialValue" SG_ 1684 sig_3_3 4.0;
BA_ "initialValue" SG_ 1684 sig_8_3 -3.0;
BA_ "initialValue" SG_ 1684 sig_11_1 1.0;
BA_ "initialValue" SG_ 1684 sig_47_3 1.0;
BA_ "initialValue" SG_ 1684 sig_59_4 -4.16227766016838E-6;
BA_ "sendPeriod" BO_ 505 25;
BA_ "crcStartValue" BO_ 505 26;
BA_ "initialValue" SG_ 505 sig_7_8 1.2500000000000009E-5;
BA_ "initialValue" SG_ 505 sig_23_14 610.0;
BA_ "sendPeriod" BO_ 1310 5;
BA_ "crcStartValue" BO_ 1310 18;
BA_ "initialValue" SG_ 1310 sig_6_14 1.0065277660168385E-4;
BA_ "initialValue" SG_ 1310 sig_7_2 1.0;
BA_ "initialValue" SG_ 1310 sig_36_11 -0.005557722339831626;
BA_ "initialValue" SG_ 1310 sig_26_6 -0.25000000000000006;
BA_ "initialValue" SG_ 1310 sig_41_2 1.0;
BA_ "frameSendMode" BO_ 567 2;
BA_ "sendPeriod" BO_ 567 1000;
BA_ "eventMinDistance" BO_ 567 500;
BA_ "crcStartValue" BO_ 567 127;
BA_ "initialValue" SG_ 567 sig_7_9 4.310000000000004E-6;
BA_ "initialValue" SG_ 567 sig_0_7 46.0;
BA_ "initialValue" SG_ 567 sig_32_8 -11400.0;
BA_ "initialValue" SG_ 567 sig_25_6 -1862.2776601683795;
BA_ "sendPeriod" BO_ 1632 20;
BA_ "crcStartValue" BO_ 1632 187;
BA_ "initialValue" SG_ 1632 sig_7_9 0.4700000000000001;
BA_ "initialValue" SG_ 1632 sig_13_6 1.2000000000000002;
BA_ "frameSendMode" BO_ 345 2;
BA_ "sendPeriod" BO_ 345 100;
BA_ "eventMinDistance" BO_ 345 100;
BA_ "crcStartValue" BO_ 345 77;
BA_ "initialValue" SG_ 345 sig_7_11 2.0982277660168393E-5;
BA_ "initialValue" SG_ 345 sig_38_8 -72.0;
BA_ "initialValue" SG_ 345 sig_31_8 147.0;
BA_ "initialValue" SG_ 345 sig_39_8 -5.837722339831626E-4;
BA_ "sendPeriod" BO_ 1918 500;
BA_ "crcStartValue" BO_ 1918 208;
BA_ "initialValue" SG_ 1918 sig_9_12 -3.1862776601683794E-4;
BA_ "initialValue" SG_ 1918 sig_8_1 1.0;
BA_ "initialValue" SG_ 1918 sig_23_15 22008.0;
BA_ "initialValue" SG_ 1918 sig_21_2 -1.0;
BA_ "initialValue" SG_ 1918 sig_39_1 1.0;
BA_ "crcStartValue" BO_ 1614 17;
BA_ "initialValue" SG_ 1614 sig_22_30 -0.034836176200000034;
BA_ "initialValue" SG_ 1614 sig_15_8 -3.1622776601683795E-5;
BA_ "initialValue" SG_ 1614 sig_16_5 -4.0;
BA_ "initialValue" SG_ 1614 sig_21_1 1.0;
BA_ "initialValue" SG_ 1614 sig_53_10 1.0500000000000003;
BA_ "frameSendMode" BO_ 858 2;
BA_ "sendPeriod" BO_ 858 1000;
BA_ "eventMinDistance" BO_ 858 50;
BA_ "crcStartValue" BO_ 858 137;
BA_ "initialValue" SG_ 858 sig_33_6 4762.27766016838;
BA_ "initialValue" SG_ 858 sig_1_13 1.9650000000000014E-4;
BA_ "initialValue" SG_ 858 sig_6_3 1.0;
BA_ "initialValue" SG_ 858 sig_7_1 1.0;
BA_ "initialValue" SG_ 858 sig_2_2 3.0;
BA_ "initialValue" SG_ 858 sig_30_8 833.7722339831621;
BA_ "initialValue" SG_ 858 sig_31_2 -2.0;
BA_ "initialValue" SG_ 858 sig_40_8 903.7722339831621;
BA_ "crcStartValue" BO_ 467 133;
BA_ "initialValue" SG_ 467 sig_24_16 0.06467776601683778;
BA_ "initialValue" SG_ 467 sig_15_16 -17152.776601683792;
BA_ "initialValue" SG_ 467 sig_46_6 19.0;
BA_ "initialValue" SG_ 467 sig_40_1 1.0;
BA_ "initialValue" SG_ 467 sig_47_1 1.0;
BA_ "sendPeriod" BO_ 1754 25;
BA_ "crcStartValue" BO_ 1754 204;
BA_ "initialValue" SG_ 1754 sig_0_10 854.0;
BA_ "initialValue" SG_ 1754 sig_7_7 11.377223398316207;
BA_ "initialValue" SG_ 1754 sig_18_5 19.0;
BA_ "sendPeriod" BO_ 923 100;
BA_ "crcStartValue" BO_ 923 7;
BA_ "initialValue" SG_ 923 sig_14_18 1.7472622339831644E-5;
BA_ "initialValue" SG_ 923 sig_0_13 -1521.0;
BA_ "initialValue" SG_ 923 sig_32_14 -7879.0;
BA_ "initialValue" SG_ 923 sig_46_2 -2.0;
BA_ "sendPeriod" BO_ 747 500;
BA_ "crcStartValue" BO_ 747 156;
BA_ "initialValue" SG_ 747 sig_1_30 29.240849016837785;
BA_ "initialValue" SG_ 747 sig_7_6 400.0;
BA_ "crcStartValue" BO_ 44 241;
BA_ "initialValue" SG_ 44 sig_0_17 0.9275900000000006;
BA_ "initialValue" SG_ 44 sig_7_7 14.0;
BA_ "initialValue" SG_ 44 sig_31_8 186.0;
BA_ "sendPeriod" BO_ 315 5;
BA_ "crcStartValue" BO_ 315 212;
BA_ "initialValue" SG_ 315 sig_3_6 6.662277660168383E-5;
BA_ "initialValue" SG_ 315 sig_4_10 1.3777223398316238E-5;
BA_ "initialValue" SG_ 315 sig_22_14 1431.5277660168379;
BA_ "initialValue" SG_ 315 sig_17_5 -11.0;
BA_ "initialValue" SG_ 315 sig_16_1 1.0;
BA_ "initialValue" SG_ 315 sig_37_11 12.4;
BA_ "sendPeriod" BO_ 1013 25;
BA_ "crcStartValue" BO_ 1013 51;
BA_ "initialValue" SG_ 1013 sig_4_5 3662.2776601683795;
BA_ "initialValue" SG_ 1013 sig_7_1 1.0;
BA_ "crcStartValue" BO_ 582 211;
BA_ "initialValue" SG_ 582 sig_2_6 -0.0018622776601683788;
BA_ "initialValue" SG_ 582 sig_0_2 3.0;
BA_ "initialValue" SG_ 582 sig_19_12 -0.02883277660168379;
BA_ "initialValue" SG_ 582 sig_23_4 0.05837722339831623;
BA_ "sendPeriod" BO_ 291 10000;
BA_ "crcStartValue" BO_ 291 183;
BA_ "initialValue" SG_ 291 sig_5_12 1.3792776601683781E-5;
BA_ "initialValue" SG_ 291 sig_6_4 -5.16227766016838E-6;
BA_ "initialValue" SG_ 291 sig_22_15 0.04052000000000002;
BA_ "initialValue" SG_ 291 sig_41_8 28.0;
BA_ "initialValue" SG_ 291 sig_40_7 77377.22339831622;
BA_ "sendPeriod" BO_ 137 1000;
BA_ "crcStartValue" BO_ 137 225;
BA_ "initialValue" SG_ 137 sig_2_6 -2.362277660168379E-4;
BA_ "initialValue" SG_ 137 sig_0_2 1.0;
BA_ "initialValue" SG_ 137 sig_26_19 304066.0;
BA_ "initialValue" SG_ 137 sig_17_9 24.0;
